VERSION "LiveWire S2 Del Mar (2024, S2DM) - Secondary CAN (DLC tap) - community reverse-engineered v0.1"

// ============================================================================
// LiveWire S2 Del Mar - Secondary CAN bus signal database
// ============================================================================
// Vehicle : 2024 LiveWire S2 Del Mar (S2DM), VIN odo ~2510 mi at capture time
// Bus     : SECONDARY CAN, tapped at the Data Link Connector [91] (JST MWT 6-way)
//           DLC pinout (from H-D EDM): pin2=W/R=CAN-H, pin5=W/BK=CAN-L,
//           pin3=BK/GN=ground, pin4=R/Y=accessory power, pins 1&6 = N/C
// Bitrate : 500000 (classical CAN, 11-bit standard IDs)
// Members : BCM (gateway/network mgr), TCU, IM, DLC   [per H-D EDM topology]
// NOTE    : PEU/RESS/EHCU/IMU/RHCM/LHCM are on PRIMARY CAN, NOT visible here.
//           Motor/inverter/BMS broadcast data is on primary; reach it via UDS
//           through the BCM gateway (0x7Ex addresses seen on this bus).
//
// Byte convention in comments: D1..D8 = SavvyCAN export columns = CAN data[0..7]
// In DBC start-bit terms below, big-endian (Motorola) signals are used where the
// capture showed BE multi-byte values.
//
// Verification method (general):
//   Isolated single-action captures, differential analysis (before/during/after),
//   cross-checked across multiple independent captures. Timestamps were logged as
//   0 (ESP32RET/A0 export bug) so sequence-order + rider action logs were used as
//   the time axis. Where a physical reference existed (odometer mi, indicated
//   speed), decoded values were checked against it.
//
// Confidence tags in comments: [CONFIRMED] cross-verified >=2 ways;
//   [STRONG] single clean capture, physically consistent; [TENTATIVE] needs more data
// ============================================================================
//
// ===== FRAME INTEGRITY (E2E) - CRACKED =======================================
// ~36 high-rate frames carry AUTOSAR-style END-TO-END protection:
//   D7 = ALIVE COUNTER, 6-bit, increments 0..63 then wraps to 0.
//   D8 = CRC-8 / SAE-J1850  (poly 0x1D, init 0xFF, xor-out 0xFF, refin/refout=NO)
//        computed over D1..D7 (the 7 preceding bytes, INCLUDING the counter).
//        This is the AUTOSAR E2E Profile-1 CRC, applied to the raw 7 payload bytes
//        WITHOUT a Data-ID prefix - a J1850-CRC E2E-like scheme, simpler than
//        textbook Profile 1 (no per-message Data ID folded into the CRC).
//   Python: crc=0xFF; for b in D1..D7: crc^=b; 8x{ crc=((crc<<1)^0x1D)&0xFF if
//           crc&0x80 else (crc<<1)&0xFF }; checksum = crc ^ 0xFF
//   PROTECTED IDs (D7=alive ctr, D8=CRC): 0x122 124 126 128 12A 131 133 134 152
//     154 15A 160 161 162 163 164 180 181 182 183 184 185 186 187 188 189 1A6
//     1A7 1C7 1C9 260 322 324 35A 3C8 562.  Verified 100% frame match. Use it to
//     VALIDATE a decode (a mis-aligned read fails CRC) and to detect dropped frames
//     (counter gaps).
//   UNPROTECTED IDs (D7 & D8 CONSTANT padding, no per-frame integrity): 0x136 138
//     261 262 326 328 332 334 338 33A 33C 33E 354 392 394 395 3C4 3C6 3CA 3CC 3CE
//     3CF. A few carry an internal counter mid-frame (0x3C4 D3, 0x3C6 D5) but no CRC.
//     NOTE: even the fast 0x326 (wheel speeds) is unprotected - protection tracks the
//     authoring module / signal criticality, not the frame rate.
//
// ===== ID-MAP PROVENANCE =====================================================
// The S2 does NOT reuse the combustion-Harley CAN map: 0x383 (radio), 0x521 (speed),
// 0x530, 0x540/0x541 (engine), 0x544 (throttle), 0x5C1 (clock) are ALL ABSENT - a
// purpose-built EV ID map, not a warmed-over platform DBC (despite shared module
// architecture). Some frames are ALLOCATED-BUT-EMPTY reserved slots: 0x394 / 0x3CA /
// 0x3CF read all-zero; 0x328 / 0x3CC are sentinel-filled (0xFF/0xFE) placeholders.
// Stack is AUTOSAR (per the E2E CRC-8/J1850); the IM is a Harley first-party module,
// software-versioned via Harley SIP (e.g. LiveWire Instrument Module 02.02.00). No
// public community CAN documentation exists for the LiveWire - this DBC is novel.
// ============================================================================
// ---- 0x122 (290) : IMU 3-AXIS ACCELEROMETER (lean/tilt) - CONFIRMED ----------
// [RESOLVED - 3-AXIS ACCELEROMETER, see BO_ below] 0x122 is not six independent bytes - it is
//   THREE 16-BIT PAIRS with an offset-binary (signed) encoding:
//     D1:D2, D3:D4, D5:D6, each with value - 32768 giving a signed number.
//   Evidence: D1, D3, D5 take only ~2 values each (~128, ~128, ~97) i.e. they are
//   HIGH BYTES sitting near the 0x8000 signed-zero point, while D2, D4, D6 sweep
//   247/241/223 distinct values as low bytes. Decoded that way the ranges are
//   sensible: D1:D2 = -56..+137, D3:D4 = -253..+37, D5:D6 = -7865..-7654.
//   WHAT THEY ARE NOT: correlated against speed, motor load, battery flow and
//   acceleration over 2469 paired samples, every r is between -0.06 and +0.08 -
//   i.e. no relationship to any vehicle dynamic we have decoded. Specifically NOT
//   battery power (that hypothesis was tested and failed).
//   These are the highest-resolution unexplained channels on the bus and the most
//   likely place for something significant still to be hiding.
//   HISTORICAL NOTE: earlier passes examined D2/D4/D6 as standalone bytes, which is
//   why they looked like noise - the pairing was the missing piece.
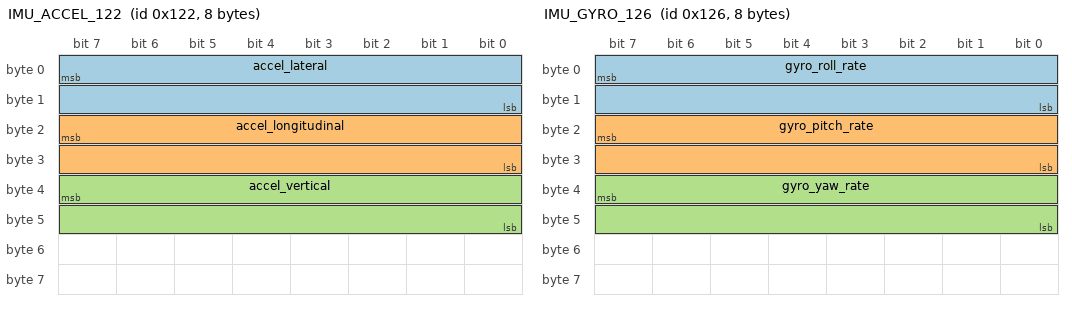
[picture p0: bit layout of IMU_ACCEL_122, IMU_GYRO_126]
BO_ 290 IMU_ACCEL_122: 8 IM
 SG_ accel_lateral      : 7|16@0+ (1,-32768) [-32768|32767] "count" Vector__XXX
 SG_ accel_longitudinal : 23|16@0+ (1,-32768) [-32768|32767] "count" Vector__XXX
 SG_ accel_vertical     : 39|16@0+ (1,-32768) [-32768|32767] "count" Vector__XXX

// [CONFIRMED] 0x122 = 3-AXIS ACCELEROMETER (IMU), gatewayed from primary CAN. Three
//   signed 16-bit channels, offset-binary (physical value = raw - 32768):
//     D1:D2 = LATERAL / roll axis    (lean LEFT = positive, lean RIGHT = negative)
//     D3:D4 = LONGITUDINAL / pitch   (level ~+175; NOSE-DOWN tilt drops it to ~-110)
//     D5:D6 = VERTICAL axis          (~ -7770 at rest = -1 g)
//   SCALE ~7770 counts per g (from the resting vertical channel).
//   PROVEN by lean_3xl_3xr (bike rocked by hand on the sidestand, 3x left then 3x
//   right):
//     - D1:D2 swung +786..+1211 on the THREE left leans and -1024..-1525 on the
//       THREE right leans - signed and symmetric by direction. Clean 3L/3R pattern.
//     - D5:D6 magnitude SHRANK toward zero on every lean (-7770 -> -7617 at hardest),
//       exactly as gravity tilts off the vertical axis.
//     - VECTOR MAGNITUDE CONSERVED: sqrt(D1D2^2 + D3D4^2 + D5D6^2) held ~7770 across
//       all orientations = a constant 1 g gravity vector rotating between axes. At
//       the biggest right lean sqrt(1525^2 + 7617^2) = 7768 ~= rest 7770. That
//       conservation is the definitive accelerometer signature.
//   Implied lean angles were gentle hand-rocks: asin(1525/7770) ~= 11 deg right,
//   asin(1211/7770) ~= 9 deg left.
//   PITCH AXIS INDEPENDENTLY VALIDATED by a natural experiment (stand geometry):
//   ordering captures by odometer, D3:D4 held ~+175 (level) through EVERY front-wheel
//   test, then STEPPED to ~-110 exactly at the forklock capture - the moment the
//   front wheel came off the stand and the bike tilted nose-down onto the rear stand
//   only. Cleanest A/B: idle_94f (front stand ON) D3:D4=+175 vs idle_forward_tilt
//   (front stand removed) D3:D4=-112 = a 287-count step = asin(287/7770) ~= 2.1 deg
//   forward tilt, while D5:D6 (vertical) and D1:D2 (lateral) barely moved - a pure
//   fore-aft rotation, exactly as a pitch axis must behave. So ALL THREE axes are now
//   independently validated (lateral=lean test, vertical=gravity magnitude, pitch=
//   stand tilt). NOTE this means the "pitch NOT found on secondary" entry in the
//   speculation doc is also overturned - it was there all along in D3:D4.
//   *** OVERTURNS the speculation-doc "tilt/lean NOT on secondary" conclusion. The
//   IMU is a primary-bus module but its accel IS gatewayed here. The reason 0x122
//   never correlated with speed/power (which killed the battery-power idea) is that
//   an accelerometer reads GRAVITY at rest, not vehicle dynamics - the tell was the
//   near-constant -7770 vertical channel all along.
//   COMPANION FRAME: 0x126 is the matching 3-AXIS GYROSCOPE (CONFIRMED) - see its
//   block immediately below. Together 0x122 (accel) + 0x126 (gyro) form a full
//   6-AXIS IMU gatewayed onto secondary CAN.
// ---- 0x126 (294) : IMU 3-AXIS GYROSCOPE (angular rate) - CONFIRMED -----------
BO_ 294 IMU_GYRO_126: 8 IM
 SG_ gyro_roll_rate  : 7|16@0+ (1,-32768) [-32768|32767] "count" Vector__XXX
 SG_ gyro_pitch_rate : 23|16@0+ (1,-32768) [-32768|32767] "count" Vector__XXX
 SG_ gyro_yaw_rate   : 39|16@0+ (1,-32768) [-32768|32767] "count" Vector__XXX

// [CONFIRMED] 0x126 = 3-AXIS GYROSCOPE (angular RATE), same structure as the 0x122
//   accelerometer: three signed 16-bit pairs, offset-binary (value = raw - 32768):
//     D1:D2 = ROLL rate    (responds to SIDE-TO-SIDE shaking)
//     D3:D4 = PITCH rate   (responds to FORWARD-BACK shaking)
//     D5:D6 = YAW rate     (third axis; responded to both hand-shakes because manual
//                           input is never a pure single axis - treat yaw as [STRONG])
//   PROVEN by shakenbabysyndrome_sidetoside_forwardback_5xeach (bike shaken on the
//   stand, 5x side-to-side then 5x fore-aft):
//     - AXIS MATCH: D1:D2 (roll) oscillated hard in the SIDE-TO-SIDE burst and went
//       quiet in the fore-aft burst; D3:D4 (pitch) did the opposite - one-to-one with
//       the 0x122 accel roll/pitch axes.
//     - RATE-NOT-ANGLE (definitive): within the side-to-side burst, D1:D2 correlates
//       r=-0.68 with the DERIVATIVE of the 0x122 roll ANGLE, and only r=-0.05 with the
//       angle itself. Angular rate = d(angle)/dt, ~90 deg out of phase with angle -
//       exactly a gyro. Peak-to-peak (7826) exceeded the accel's (4362), as expected
//       for a rate driven by fast motion.
//   SCALE: raw counts; deg/s per count NOT pinned (needs a known rotation rate, e.g. a
//   turntable - not worth chasing for a display/telemetry feed).
//   HISTORY: 0x126 was long dismissed as noise / "0xFFFE not-available". The sentinel
//   just means that gyro axis is idle/unpopulated in some states; under motion all
//   three pairs come alive. With 0x122 (accel) this completes the IMU on secondary.
// ---- 0x128 (296) : PROPULSION / ABS STATUS (E2E, sparse ~0.2 Hz) -----------
BO_ 296 PROPULSION_ABS_128: 8 Vector__XXX
 SG_ front_brake_applied_128 : 47|8@0+ (1,0) [0|255] "" Vector__XXX

// [CANDIDATE 2026-07-29 — "triangle-!" whole-suite WARNING-ICON fingerprint] Rider triggered the dash
//   warning icon on a real ride (s60) and rebooted to clear it (s61). An A/B (s60 warning vs s61
//   cleared-post-reboot + s59 normal, all controlled for riding) isolates a LATCHED ABS/traction
//   signature persisting until power-cycle, across THREE EHCU/motor frames:
//     0x128 D5 : 0x10 -> 0x70        (this frame's hard-decel/ABS-regen control block, heavily flagged)
//     0x161 D6 : 0x04/0x14 -> 0x74   (motor_status: extra 0x60 bits above the 0x10 limiter = DERATE)
//     0x3C8 D3 : 0x3F/0xDF -> 0xFF   (ABS status/validity word, all bits)
//     0x505 D1 : 0x00 -> 0x01        (latched power/boot flag)
//   All ABS/TC/limiter-class => matches the rider's "ABS/TC warning" read, and the motor-derate bit
//   implies it also LIMITS power (limp mode). RULES OUT the old 0x152 D2=0x0E lighting telltale (0x00
//   here). MODE CONFOUND REMOVED: the normal ride s59 was the SAME mode as s60 (0x44 = Eco/Range) yet
//   shows the NORMAL values, so the latch is warning-specific, NOT mode-driven. Remaining CAVEAT:
//   single occurrence, no onset, no live DTC captured. Confirm with the ONSET + a live DTC read while
//   the warning is present. See docs/livewire_s2_CAN_speculation.md.
// [CONFIRMED 2026-07-29 — 6-session review] D6 (front_brake_applied_128) = FRONT-BRAKE-APPLIED flag:
//   0x01 off / 0x02 on. Thresholded with hysteresis on the 0x324 front-brake pressure (sets ~200-270
//   raw, clears ~90-130). D6 vs 0x324 r = +0.81..0.91 across SIX sessions. DISCONFIRMED as rear/regen
//   by the s57 hard-regen event (tq=-260, rbrk=16, fbrk=0 -> D6 stayed 0x01). SUPERSEDES the frame-
//   catalog "0x128 D6 = 2-state status bit, unattributed." (EHCU/ABS = Bosch MSC; a front-pressure
//   threshold flag is native to that unit.)
//   D3/D4/D5 = [CANDIDATE] hard-decel / regen-control block - activate together ONLY during sustained
//   strong regen/hard braking (zero at standstill/cruise/accel; dissociated from the front-brake
//   flag: active with fbrk=309 in s28 AND fbrk=0 in s57, common factor tq~=-198 regen). D5 0x20 =
//   control-active bit; D3 = phase index {18,19}; D4 = 0-211 sawtooth (ABS/regen-blend modulation
//   output, NOT a clean magnitude). Single-event-per-session -> needs a graded/near-ABS braking
//   capture to settle (see the 0x128 census caveat + speculation doc). D7/D8 E2E.
// ---- 0x12A (298) : off-throttle / regen-active flag -------------------------
BO_ 298 STANDSTILL_FLAG_12A: 8 Vector__XXX
 SG_ standstill : 31|8@0+ (1,0) [0|255] "" Vector__XXX

// [UPDATE 2026-07-27 — ride1 real-timestamp capture + deep review; double-verified.
//  RETRACTS "off_throttle_regen". 0x12A D4 = 0x40 is a debounced VEHICLE-STANDSTILL
//  flag (Bosch-style), NOT a regen indicator.]
//   Sets ~0.4 s after speed reads 0; clears ~0.34-0.56 s after sustained motion;
//   THROTTLE-INDEPENDENT (held through 22.5% launch throttle at 0 km/h). Transitions
//   ride the normal 200 ms grid.
//   REGEN MODEL KILLED BOTH WAYS: 0x00 through the ENTIRE 75mph passive-regen coast
//   and every ride1 regen phase; 0x40 held while throttle applied at standstill.
//   Corpus-wide: ZERO instances of 0x40 while moving (a hard invariant -> validate.py).
//   [REVERSE CORROBORATION 2026-07-30, ultracode] D4 is a standstill/drive-engaged flag, NOT a
//     direction bit: 0x00 in BOTH reverse-drive AND forward-drive, 0x40 only at idle/standstill
//     (reverse2x: 0x00 in 34 reverse-drive + 43 forward-drive rows, 0x40 in 124 idle rows). It
//     is the sole status byte that moves between regimes, and it tracks engagement not direction.
//   The old "0x40 during coast/regen" reading was standstill coincidentally co-occurring
//   with the end of those low-speed bench tests.
//   QUALIFIED: standstill is NECESSARY but not SUFFICIENT - a gating condition also
//   applies (candidates: dynamics-suite-valid, or 0x162 D4 state; ~5 s power-on
//   latency; 0x40 absent in gyro-0xFFFE rows). D4=0x80 is a THIRD state seen only in
//   mode-sweep captures, coincident with 0x134 entering/leaving 0x55/0x88/0x99 at
//   standstill (mode-hold). Both unresolved - see the speculation doc.
//   *** [RETRACTED 2026-07-29 — was "[NEW 2026-07-28] 0x12A D1 = a 2-LEVEL SPEED-BAND FLAG (0x40
//   rest/low, 0x80 above a speed threshold)"]: the speed-band read FAILS on full speed overlap -
//   s54 has 945-raw speed at 0x40 vs 237-raw at 0x80, so the two levels' speed distributions fully
//   OVERLAP. What actually happens: 0x12A D1 = a MOTION-GATED PARITY/ALTERNATION bit - it flips
//   0x40<->0x80 on essentially every consecutive MOVING frame (alternation 0.92/1.00/1.00/1.00 over
//   s28/s31/s44/s57) and is pinned to 0x40 at standstill. 0x80 is simply SUPPRESSED at standstill,
//   which is why its mean speed looked higher earlier (a gating artifact, not a speed band). Toggle
//   PASS (deterministic, 4 sessions); NOT a signal to wire. (Old speed-band means kept above for the
//   record: they were the standstill-suppression artifact, not a threshold.) ***
// ---- 0x133 (307) : see IGNITION_REAR_BRAKE_133 below (merged) ---------------
// ---- 0x134 (308) : RIDER SETTINGS status (mode + TC + related) ---------------
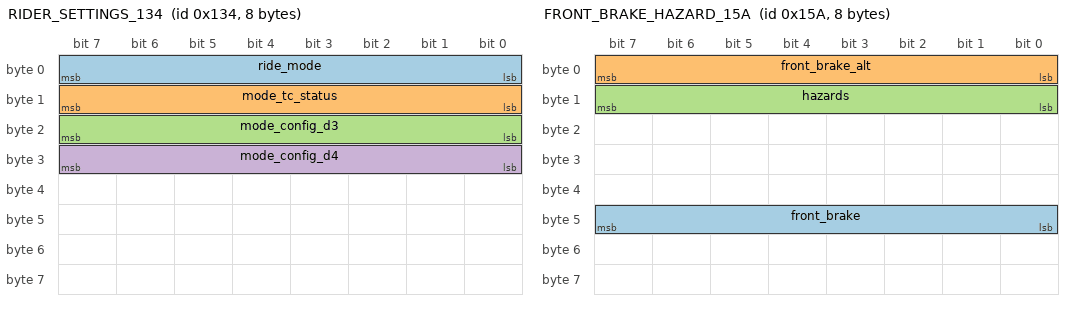
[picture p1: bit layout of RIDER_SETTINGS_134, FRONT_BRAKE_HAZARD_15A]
BO_ 308 RIDER_SETTINGS_134: 8 BCM
 SG_ ride_mode      : 7|8@0+ (1,0) [0|255] "" Vector__XXX
 SG_ mode_tc_status : 15|8@0+ (1,0) [0|255] "" Vector__XXX
 SG_ mode_config_d3 : 23|8@0+ (1,0) [0|255] "" Vector__XXX
 SG_ mode_config_d4 : 31|8@0+ (1,0) [0|255] "" Vector__XXX

// [CONFIRMED] 0x134 D1 = ride-mode enum (high nibble = mode id):
//   0x22 Sport, 0x11 Street, 0x44 Eco, 0x33 Rain, 0x88 custom-A, 0x99 custom-B,
//   [NAMING 2026-07-29] "Street"/"Eco" were the rider's labels; per the OEM manual the factory modes
//   are Sport/Road/Range/Rain/Flat Track -> 0x11 Street = ROAD, 0x44 Eco = RANGE (Custom A/B are the
//   two app-programmable slots). All seven codes now confirmed via 3 mode-cycle captures.
//   0x55 = SEVENTH MODE (see below). Verified by cycling Sport->A->B->Rain->Eco->
//   Street->Sport and observing 0x134 D1 step 22->88->99->33->44->11->22 (clean
//   closure). 0x260 D1 mirrors.
// [CONFIRMED] 0x55 = FLAT TRACK MODE (the "hard lean" rider icon). Rider confirms
//   the leaning-rider mode IS Flat Track. It is reached by "activating" (hold Mode
//   in) SPORT: activating Sport does NOT keep id 0x22 with an overlay bit - it SWITCHES
//   the mode id to 0x55 (seen twice in modes_alltryactivated: 22 -> 55 -> 22 -> 55). So
//   Flat Track is Sport's activated variant, promoted to its own dedicated mode id.
//   It runs the Sport-tier power index (D3 low-nibble = 3, D4=0x30) with rear ABS off
//   (0x3C8 D4 bit7 set), its own default TC nibble (D2 = 0x54; low-nibble 4, distinct
//   from Sport's 3), and TC is still rider-toggleable to off (D2 = 0x59, low-nibble 9 -
//   confirmed by the modes_alltryactivated finale where the rider hand-disabled TC in
//   Flat Track: D2 went 0x54 -> 0x59). NOTE: this is NOT the "triangle-!" fault state
//   the rider once hit - Flat Track cuts REAR ABS ONLY and keeps TC available; the
//   fault dropped the WHOLE aid suite (TC + front & rear ABS). See 0x3C8 / fault notes.
// [CONFIRMED] THE "ACTIVATED" MODE VARIANT (hold the Mode button). Marked on the bus by
//   0x134 D3 HIGH NIBBLE 1 -> 4 (power-index low nibble UNCHANGED) and 0x134 D6 bit2
//   (0x04). Full sweep of activating all 7 modes (modes_alltryactivated) shows only
//   THREE modes have a functional activated variant, and each SWITCHES/overlays thus:
//     Sport (22) -> FLAT TRACK, id 0x55, D3=43, D6=04   (own mode id)
//     CustA (88) -> "Purple A",       D3=48, D6=04   (id stays 88, purple display)
//     CustB (99) -> "Purple B",       D3=49, D6=04   (id stays 99, bold/purple display)
//   Street/Rain/Eco: activating them produces NO change on secondary CAN at all (D3
//   high-nibble stays 1, D6 stays 0, rear ABS stays on) - matches rider's "only Sport
//   ->Flattrack and A/B->Purple were noticeable".
//   *** ACTIVATED vs REAR ABS OFF = SEPARATE axes, correlated only by CURRENT CONFIG. ***
//   Custom A/B are USER-PROGRAMMABLE from the LiveWire app, so what a mode's "activated"
//   variant DOES (rear ABS, TC, power) is itself configurable. The 100% co-occurrence we
//   see (every activated variant here also cuts rear ABS) therefore reflects how THIS
//   bike's A/B (and the factory Flat Track) are currently programmed - NOT an intrinsic
//   bus-level equivalence. Read the two signals as independent:
//     - 0x134 D6 bit2 / D3-hi=4  = "activated variant engaged" (generic state flag)
//     - 0x3C8 D4 bit7            = "rear ABS disabled" (a CONSEQUENCE that the mode's
//                                   programmed settings may or may not include)
//   The firmware keeps them as separate signals precisely because they are independently
//   configurable. DEFINITIVE DECOUPLE (now controllable, no fault needed): in the app,
//   program custom A's activated variant to KEEP rear ABS on, then capture - D6 bit2 will
//   set while 0x3C8 D4 bit7 stays 0. That single capture converts this from "correlated
//   under current config" to a clean independent proof. Until then: do NOT infer rear ABS
//   state from the activated flag or vice-versa; match each bit to its own frame.
// [CONFIRMED] 0x134 D2 = mode(high nibble) + status(low nibble). Low nibble
//   carries Traction Control state: within Sport, TC-on=0x23, TC-off=0x29
//   (i.e. low nibble 3=on, 9=off). Verified via idle TC-on->TC-off capture
//   (single toggle 0x23->0x29 at the switch press) AND independently the whole
//   75mph TC-off run read 0x134 D2 = 0x29 throughout.
//   CAUTION: D2 is a mode+status bitfield, not a pure TC bit. Match the low
//   nibble for TC, use D1 for mode. Other modes may set other low-nibble values
//   (Rain/Eco seen with different low nibbles) - treat unseen values as unknown.
// [CONFIRMED per-mode] 0x134 D3 and D4 are PER-MODE CONFIG bytes - each takes a
//   DETERMINISTIC value for every one of the 6 modes (cyclemodes capture):
//     mode    D1  D3  D4    0x260 D2
//     Sport   22  13  30    20
//     Street  11  11  10    10
//     Eco     44  1D  D0    40
//     Rain    33  2C  C0    30
//     CustA   88  18  80    80
//     CustB   99  19  90    90
//   ACTIVATED VARIANTS (hold Mode; D3 high-nibble=4, D6 bit2=1, rear ABS off):
//     FlatTrk 55  43  30    50   <- activated SPORT = Flat Track (own mode id 0x55)
//     PurpleA 88  48  80    80   <- activated CustA (id stays 88)
//     PurpleB 99  49  90    90   <- activated CustB (id stays 99)
//   (Street/Rain/Eco have NO functional activated variant on the bus.)
//   STRUCTURE: 0x134 D3 low-nibble == D4 high-nibble == a per-mode index
//   (3/1/D/C/8/9 for Sport/Street/Eco/Rain/CustA/CustB), and 0x260 D2 high-nibble
//   mirrors the mode id. So these carry the mode's SETTINGS bundle (regen level,
//   power map, throttle map). SEMANTIC split of the sub-fields is UNRESOLVED - would
//   need ground truth on each mode's actual regen/power settings to attribute which
//   nibble is which. For now: deterministic per-mode, usable to read the active mode
//   three independent ways (D1, D3/D4 index, 0x260 D2).
// ---- 0x15A (346) : FRONT brake lever + hazards ------------------------------
BO_ 346 FRONT_BRAKE_HAZARD_15A: 8 BCM
 SG_ front_brake : 47|8@0+ (1,0) [0|255] "" Vector__XXX
 SG_ front_brake_alt : 7|8@0+ (1,0) [0|255] "" Vector__XXX
 SG_ hazards     : 15|8@0+ (1,0) [0|255] "" Vector__XXX

// [CONFIRMED] 0x15A D6 = FRONT brake lever: 0x00 released -> 0x40 pressed.
// [CONFIRMED] 0x15A D1 = SECOND front-brake indicator: 0x10 released -> 0x01
//   pressed. Perfectly correlated with D6 (224 frames at 0x01 while pressed,
//   6736 at 0x10 while released, zero disagreement) in the fast-spin + 3x front
//   brake capture. Either byte works; D1 is a cleaner 2-state read.
//   Isolated in brakelight_front_rear_passiveregen capture: active ONLY during
//   the front-brake segment, not rear, not regen. (0x15A D1 also moves front:
//   0x10->0x01.) 0x15A D2 remains hazards (0x00<->0x10) - same frame, diff byte.
// ---- 0x133 (307) : ignition + REAR brake ------------------------------------
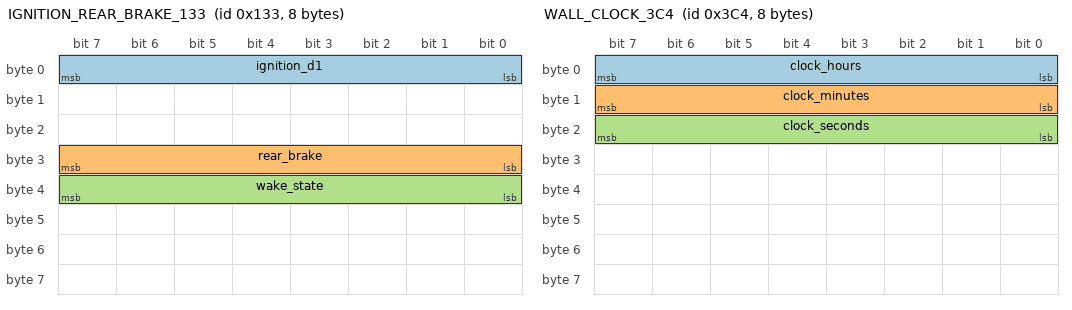
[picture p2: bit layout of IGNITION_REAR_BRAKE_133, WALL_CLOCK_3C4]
BO_ 307 IGNITION_REAR_BRAKE_133: 8 BCM
 SG_ ignition_d1 : 7|8@0+ (1,0) [0|255] "" Vector__XXX
 SG_ rear_brake  : 31|8@0+ (1,0) [0|255] "" Vector__XXX
 SG_ wake_state  : 39|8@0+ (1,0) [0|255] "" Vector__XXX

// [CONFIRMED 2026-07-28] 0x133 D5 = WAKE / ignition sub-status. 0x10 = awake/on in
//   EVERY powered state (idle E0, ride E0, charge 50), 0x20 = deep-off (only appears
//   in the ignition/boot transient alongside D1=0x20 OFF). Zero counterexamples across
//   the corpus; E2E CRC-clean. Distinct from D1 (system-state enum) - a coarser on/off.
// [CONFIRMED] 0x133 D4 = REAR brake lever: 0x00 released -> 0x10 pressed.
//   Isolated: active ONLY during the rear-brake segment (first time rear was
//   pressed in any capture). Front and rear are SEPARATE IDs - that's why the
//   earlier single-byte 0x136 guess failed.
//   ROBUSTNESS: rear LAMP was physically UNPLUGGED during this capture, yet
//   0x133 D4 still toggled cleanly => it is the LEVER SWITCH state, independent
//   of the bulb. No rear-bulb-out fault flag appeared on secondary in this
//   capture (a bulb-out fault, if any, may be on primary CAN or via UDS only).
// [CONFIRMED] 0x133 D1 = SYSTEM STATE enum (not just ignition on/off):
//     0x20 = OFF
//     0x60 = ignition ON, motor NOT enabled (accessory / stand-by)
//     0x80 = ENABLING (brief transitional state during START press)
//     0xE0 = MOTOR ENABLED / ready-to-drive
//     0x50 = CHARGING (AC charging in progress). CONFIRMED: appears in 2025 frames
//            of charge_1-1kw.csv and in NONE of the other 46 captures. The capture
//            also contains 0x60, i.e. it moves between charging and ignition-on.
//   Mapped with the full ign->enable->roll->brake->disable->off sequence capture.
//   (An earlier ignition-only capture never enabled the motor, so it only ever
//   showed 0x20/0x60 - hence the earlier incomplete "on/off" decode.)
// ---- 0x152 (338) : lighting + ignition bitfields ----------------------------
BO_ 338 LIGHTING_152: 8 BCM
 SG_ highbeam   : 23|8@0+ (1,0) [0|255] "" Vector__XXX
 SG_ ign_152_d2 : 15|8@0+ (1,0) [0|255] "" Vector__XXX

// [STRONG] 0x152 D3 = high beam: 0x00<->0x04. Verified highbeam_on_2x capture.
//   D2 (byte 1) is a shared lighting/ignition bitfield (0x00/0x10/0xE0 at ignition) AND
//   carries a LATCHED WARNING TELLTALE at value 0x0E: 0x00 normal -> 0x0E warning, held ON
//   even at a standstill from ride session s15 onward (motion-INDEPENDENT, so NOT a headlight
//   beam), with NO stored DTC (rider ran diagnostics -> "no faults"). Rider attributes it to
//   an ABS/TC-related warning. [RIDE-CONFIRMED 2026-07-28; corrects the earlier "D2 = beam
//   bitfield" reading for the 0x0E value — that specific value is a warning telltale.]
// ---- 0x131 (305) : turn signal LAMP STATUS (live bulb on/off + side) --------
BO_ 305 TURN_LAMP_131: 8 BCM
 SG_ lamp_left  : 23|8@0+ (1,0) [0|255] "" Vector__XXX
 SG_ lamp_right : 31|8@0+ (1,0) [0|255] "" Vector__XXX

// [CONFIRMED] 0x131 D3/D4 = LAMP STATUS (blinks at flash cadence = live bulb):
//   resting (off) = (D3=0x15, D4=0x50).
//   Left lamp lit : D3 0x15 -> 0x19   (blinks ~16 frames off / 17 on)
//   Right lamp lit: D4 0x50 -> 0x90   (blinks)
//   Hazards       : BOTH D3 and D4 blink (0x19 / 0x90)
//   This is the LAMP layer: D3/D4 oscillate ON<->OFF at the flash rate, so a
//   snapshot tells you whether that bulb is CURRENTLY lit. Use for a live blink
//   effect. Decode side: left uses D3, right uses D4.
//   Verified: left_signal_2x (only D3 blinks), right_signal_2x (only D4 blinks),
//   hazards_2x (both blink), idle (neither) captures.
// [REFINED 2026-07-29 — was "0x154 D4/D5 ... repeater artifact, do not use for turn state"]
//   0x154 D4/D5 is a STRUCTURED L/R TURN-SIGNAL REPEATER lane (promoted to BO_ 340 below), NOT
//   noise: every D4=0x10 aligns to 0x131 D3=0x19 (LEFT lit), every D4=0x01 aligns to 0x131 D4=0x90
//   (RIGHT lit), and D5=0x10 fires on the off-phase edges between D4 pulses. ~25 clean events across
//   s54+s57 with ZERO disagreement. 0x131 D3/D4 REMAINS the lamp source; 0x154 is a downstream echo
//   (usable as an L/R repeater, not as the primary turn state).
// ---- 0x154 (340) : TURN-SIGNAL REPEATER LANE (E2E) -------------------------
BO_ 340 TURN_REPEATER_154: 8 BCM
 SG_ turn_repeater_lr       : 31|8@0+ (1,0) [0|255] "" Vector__XXX
 SG_ turn_repeater_offphase : 39|8@0+ (1,0) [0|255] "" Vector__XXX

// [STRONG 2026-07-29] Downstream repeater of the 0x131 turn lamps: D4 (turn_repeater_lr) 0x10 =
//   LEFT (aligns 0x131 D3=0x19), 0x01 = RIGHT (aligns 0x131 D4=0x90); D5 (turn_repeater_offphase)
//   0x10 fires on the off-phase edges between D4 pulses. ~25 clean events s54+s57, zero disagreement.
//   0x131 remains the lamp SOURCE - this is an echo lane. D1/D2 = [CANDIDATE] extra Slow-mode
//   indicator lanes (0x01/0x10, single session s57, not turn-driven; see speculation doc). D7/D8 E2E.
// ---- 0x3C4 (964) : UNKNOWN (contains rolling counters) ----------------------
BO_ 964 WALL_CLOCK_3C4: 8 BCM
 SG_ clock_hours   : 7|8@0+ (1,0) [0|23] "h" Vector__XXX
 SG_ clock_minutes : 15|8@0+ (1,0) [0|59] "min" Vector__XXX
 SG_ clock_seconds : 23|8@0+ (1,0) [0|59] "s" Vector__XXX

// [CONFIRMED 2026-07-28, frame-catalog + empirical verify] 0x3C4 D1:D2:D3 = REAL-TIME
//   CLOCK, hours:minutes:seconds. In newcap_4 (real timestamps) D3 (seconds) ticks +1/s
//   and wraps at 0x3B=59 exactly as D2 (minutes) increments; D1 = hours-of-day (max 0x17=23).
//   Clock advanced 116 s over 116 s of real time (ratio 1.003); 0 range violations. Free-
//   running through the ~8-min IM brownout (D2 38->46 across the gap) -> a wall clock, NOT
//   an uptime counter.
//   [REFINED 2026-07-30, ultracode round - cross-capture] 1:1 advance RE-CONFIRMED (s57
//   1502 clock-s over 1501.5 real-s, ratio 1.0003, monotonic). NOT civil-UTC-synced: the
//   clock-to-filename offset is a CONSTANT +6h38m across s57/s61/s60/s59/s28 (~10 s spread),
//   not the +7h that July PDT (UTC-7) would require -> a FREE-RUNNING clock with a fixed
//   offset (~22 min short of UTC), NOT GPS/civil-time-locked. Retracts the "GPS-synced" guess.
//   *** RESOLVES the old "0x3C4 D2 multi-purpose status byte" TODO: the "turn-intent"
//   0x0E/0x10/0x14 and the ABS-test 0x15/16/17 values were simply the MINUTES-of-recording
//   of those captures. RETRACTS notes.md's "No wall clock" claim. ***
//   D4=0x00, D5=0x30, D6=0x03 constant. Use 0x131 D3/D4 for turn state, not this.
// ============================================================================
// ROUND-6 FRAME CATALOG (2026-07-28) - the frames previously dismissed as
//   "reserved / heartbeat / echo", each now characterized. 9/18 carry real state,
//   7 confirmed inert. FULL per-ID detail + evidence: docs/livewire_s2_CAN_frame_catalog.md
// ============================================================================
// ---- 0x136 (310) : BCM DRIVE-READY STATE MACHINE (non-E2E, ~1 Hz) ----------
BO_ 310 DRIVE_READY_136: 8 BCM
 SG_ drive_ready_state : 7|8@0+ (1,0) [0|255] "" Vector__XXX

// [STRONG] D1 enum: 0x44 = drive-ENABLED/RUN, 0x33 = powered READY-but-not-enabled (D2/D3/D6
//   coded redundantly: 41/10/FD run vs 32/20/FC ready). Deterministic power-up sweep then
//   settles; flips to ENABLED only after the roll-enable step. = propulsion enabled vs standby.
// ---- 0x138 (312) : BCM LIVENESS HEARTBEAT (non-E2E) ------------------------
BO_ 312 HEARTBEAT_138: 8 BCM

// [CONFIRMED inert] Fixed payload D2=0x40 (else 0x00) in all 61 captures incl. the brownout
//   fault. No counter/CRC. Value is presence-only (module liveness).
// ---- 0x184 (388) : VSC PROPULSION STATUS (E2E, ~2.5 Hz) --------------------
BO_ 388 PROPULSION_STATUS_184: 8 Vector__XXX
 SG_ drive_state_184     : 39|8@0+ (1,0) [0|255] "" Vector__XXX
 SG_ tc_intervention_184 : 47|8@0+ (1,0) [0|255] "" Vector__XXX

// [STRONG] D5 (drive_state_184) speed-INVERSE (r=-0.80 vs rpm): 30 coast->20 moving->10 hard.
//   D6 (tc_intervention_184) flat 0xF0, steps F0->F1->F2 only in ride1 TC/slip = intervention
//   event indicator. D3/D4 = readiness bits (7D/90, 19/00). D7/D8 E2E. (Refines the old
//   "mostly-static; USB red-herring" note - the USB retraction stands, D5 is speed-linked.)
// [CORROBORATED 2026-07-28, s44 real timestamps] D6 fired 4 genuine TC micro-interventions
//   (F0->F1) on the hard launches: t=207.2 (thr 52%, td 542), t=333.8 (thr 80%, td 878,
//   rear-lead 44), t=335.7 (thr 34%, td 304), t=338.9 (thr 51%, td 516) - each lines up with a
//   >6% rear-wheel-lead episode (0x326) => real driven-wheel slip cut by an ACTIVE TC (TC ON,
//   rear ABS ON, no burnout, rear-lead max 8.5%). First TC micro-cuts captured on the streamed
//   corpus, confirming the D6 = TC-intervention read on true timing.
// [REFINED 2026-07-29 r1 — GRADED, not flat-0xF0] The identity (D6 = TC/slip intervention)
//   holds, but the "flat 0xF0 except discrete slip events" prose is WRONG. Under sustained fast
//   riding D6 is CONTINUOUSLY active across a graded band F0-FC with a DECAYING distribution
//   (s57: F0 27%, F1 43%, tapering off to FC) - it is a slip-intervention INTENSITY, not a
//   binary flag and not a uniform counter. The s44 discrete F0->F1 micro-cuts (each aligned to a
//   >6% rear-wheel-lead) remain valid as the low end of that same continuum.
// [CANDIDATE 2026-07-29 — pack-thermal / power-derate cluster] (comments only, not wired):
//   D1 = coarse pack-THERMAL / derate LEVEL index (range 25-30, ~6 levels; pinned 28 in
//   gentle/parked captures). In the hard s55 run (pack raw 81->101 = 41->61 degC) D1 correlates
//   r=+0.92/+0.93/+0.93 with the three 0x183 pack temps and -0.93 vs ambient.
//   *** DOWNGRADED to SPECULATIVE / UNRESOLVED 2026-07-29 r1 (adversarial QA - fails cross-session). ***
//   The single-ride s55 r=0.92 is a temp/SoC/time-COLLINEAR co-trend, and the cross-session
//   absolute levels are NON-MONOTONIC: D1 is pinned at EXACTLY 28 in 11/13 sessions spanning pack
//   temp 78-83 raw, yet s54 (pack 80-81 raw) reads 25-26 - BELOW the COOLER park sessions
//   (78-79 raw -> 28). If D1 rose with pack temp, the warmer s54 should read >= park's 28, not
//   less. This STRIKES the earlier "SURVIVES the disconfirmer: s54 stayed cool -> D1 low"
//   rationalization - s54 was NOT cool for the pack (80-81 raw) and still read low, which
//   refutes rather than confirms a temp/derate index. Purpose unresolved; do NOT wire.
//   D4 bit0 = readiness / power-NOT-limited flag: 0x19 (bit0=1) at light load -> 0x18 (bit0=0) under
//   heavy propulsion demand; clean split by drive_state_184 (D5) hi-nibble (0/1/2 light -> 9-15 hard).
//   D2/D3 = [SPECULATIVE] propulsion derate substate: D3 base 0x7D becomes a +1/frame rolling counter
//   in low-SoC/derate windows (refines the old "D3 = readiness bits 7D/90" - 0x90 was one counter
//   value); D2 hi-nibble = idle 0x50. Trigger unpinned - see speculation doc.
// ---- 0x186 (390) : HV ENERGY METER (E2E, ~1.8 Hz) -------------------------
BO_ 390 HV_ENERGY_186: 8 Vector__XXX
 SG_ trip_energy_consumed_wh  : 7|16@0+ (1,0) [0|65535] "Wh" Vector__XXX
 SG_ pack_energy_remaining_wh : 23|16@0+ (1,0) [0|65535] "Wh" Vector__XXX

// [CONFIRMED] D1:D2 (16-bit BE) = TRIP ENERGY CONSUMED since key-on, ~1 Wh/count. Up-counts on
//   discharge, DOWN-steps in regen, resets ~0 at key-on, clamps 0 while charging. Magnitude
//   scales with ride energy (s31 gentle ~40 Wh -> s55 hard ~2600 Wh -> s57 long ~3768 Wh) and
//   matches integral(0x181 V*I) to order (s55 ~2.9 kWh est vs 2600 Wh). WIDENS the old D2-only
//   8-bit meter (was hv_energy_wh) to the full 16-bit D1:D2 word - same physical meter.
// [UPDATE 2026-07-29 — 8-session review] D3:D4 (16-bit BE) = PACK ENERGY REMAINING, ~1 Wh/count.
//   Ratio 102.8-104.1 Wh per displayed-SoC% across all 8 non-trivial captures (22-100% span);
//   full = 10158-10300 Wh = the S2's ~10.3 kWh usable pack (independent spec anchor); 2277 Wh at
//   22% SoC (0.22*10300~=2266, matches). Steps DOWN on discharge, UP on charge (bidirectional).
//   *** RETRACTS the old "D3 = slow status band 0x25-0x28 [OPEN]" and "D4 = companion byte [OPEN]"
//   notes: the 0x25-0x28 band was simply the high byte at high SoC (0x25-0x28 = 9.5-10.3 kWh). ***
//   D5 [CANDIDATE, unwired] latches ~74 during CC charge (single charge session s32) - SPECULATIVE.
//   D7/D8 E2E.
// ---- 0x187 (391) : IM CLUSTER HEALTH (E2E, ~1.6 Hz) -----------------------
BO_ 391 IM_HEALTH_187: 8 Vector__XXX
 SG_ im_health : 23|8@0+ (1,0) [0|255] "" Vector__XXX

// [STRONG] D3 = IM cluster health: 0xA2 operational / 0x90 initializing-or-just-reset. Goes
//   0x90 exactly as the E2E alive-counter restarts at 0x01 (boot + at the fault restart in
//   faulted_IMoff_restarted) = catches the cluster browning out. D2=0x01 sub-type tag.
// ---- 0x189 (393) : IM TELLTALE + DRIVE DEMAND (E2E, ~17 Hz) ----------------
BO_ 393 IM_TELLTALE_189: 8 Vector__XXX
 SG_ throttle_demand : 31|8@0+ (1,0) [0|255] "" Vector__XXX
 SG_ wheelspin_event : 15|8@0+ (1,0) [0|255] "" Vector__XXX

// [CONFIRMED 2026-07-28 empirical verify] D4 (throttle_demand) = throttle/drive-demand,
//   corr +0.958 (newcap_8) / +0.869 (ride1) vs 0x161 throttle. *** CORRECTS the old "rolling
//   counter" label for this byte. *** D2 (wheelspin_event) = 0x01 ONLY in ride1 slip + ride3
//   burnout (traction-event flag). D1/D3 = broad telltale levels, D5 = blink/dim PWM phase.
// ---- 0x261 (609) / 0x262 (610) : BCM POWER-AVAILABILITY STATUS (non-E2E) ---
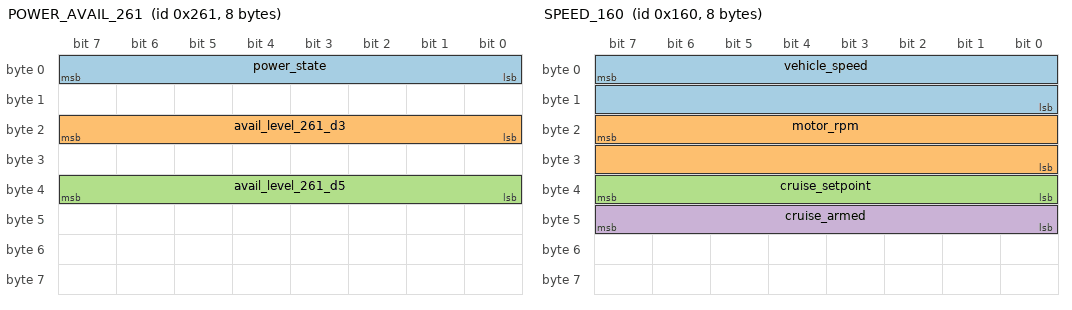
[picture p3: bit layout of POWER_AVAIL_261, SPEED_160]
BO_ 609 POWER_AVAIL_261: 8 BCM
 SG_ power_state        : 7|8@0+ (1,0) [0|255] "" Vector__XXX
 SG_ avail_level_261_d3 : 23|8@0+ (1,0) [0|255] "" Vector__XXX
 SG_ avail_level_261_d5 : 39|8@0+ (1,0) [0|255] "" Vector__XXX

BO_ 610 POWER_AVAIL_262: 8 BCM
 SG_ power_state_mirror : 39|8@0+ (1,0) [0|255] "" Vector__XXX

// [STRONG] D1 (power_state) packed: hi-nibble A=fault/init D=drive-ready E=charge/accessory;
//   lo-nibble availability. Live within-capture transitions (faulted E0->D0->AF; ks_up EC->DC).
//   0x261 D1 == 0x262 D5 exactly (internal mirror). D3/D5 = availability levels (full vs
//   reduced). *** REFUTES the old "0x261/262 BOOT-CONFIG constant" speculation: live power-
//   domain / availability STATUS, mode-independent. ***
// ---- 0x328 (808) : RESERVED SENTINEL (non-E2E) ----------------------------
BO_ 808 RESERVED_328: 8 Vector__XXX

// [CONFIRMED inert] Single payload [00 FF F0 00 00 00 00 00] across all 2019 frames / 64
//   captures. Allocated-but-empty. (Sentinel bytes are FF/F0, not FF/FE.)
// ---- 0x33C (828) / 0x3CE (974) : TWO-PHASE HEARTBEAT PAIR (non-E2E) --------
BO_ 828 HEARTBEAT_33C: 8 Vector__XXX

BO_ 974 HEARTBEAT_3CE: 8 Vector__XXX

// [CONFIRMED inert] 0x33C strictly alternates two fixed payloads A/B every-other-frame
//   (~50% duty - NOT the old "~5% cadence"): A=[40 00 00 01 09 40 80 00], B=[50 00 01 00 00
//   00 80 00]. 0x3CE is its pair (D1 toggles 0x40/0x50, [01 09 40] motif fixed). Liveness only.
// ---- 0x33E (830) : KEEPALIVE HEARTBEAT (non-E2E) --------------------------
BO_ 830 HEARTBEAT_33E: 8 Vector__XXX

// [CONFIRMED inert] Fixed payload [00 00 00 00 00 00 60 00]; only D7=0x60 marker, never
//   increments. Keepalive/liveness only.
// ---- 0x3C6 (966) : ODOMETER ECHO (non-E2E, ~3 Hz) -------------------------
BO_ 966 ODOMETER_ECHO_3C6: 8 Vector__XXX
 SG_ odometer_echo_m : 15|24@0+ (1,0) [0|16777215] "m" Vector__XXX
 SG_ odo_valid       : 47|8@0+ (1,0) [0|255] "" Vector__XXX

// [CONFIRMED] D2:D3:D4 = unprotected ECHO of the 0x562 odometer (median lag 214 ms, never
//   leads). D6 (odo_valid) = 0x30 once the odometer is valid, 0x00 during boot. Consumed by
//   the TCU. No independent content - do not read as a separate distance.
// ---- 0x3CA (970) / 0x3CF (975) : RESERVED (all-zero, non-E2E) --------------
BO_ 970 RESERVED_3CA: 8 Vector__XXX

BO_ 975 RESERVED_3CF: 8 Vector__XXX

// [CONFIRMED inert] Both all-8-bytes-0x00 in every capture. Allocated-but-empty slots in the
//   0x3Cx chassis cluster.
// ---- 0x3CC (972) : CHASSIS FAULT LATCH (non-E2E, ~0.6 Hz) ------------------
BO_ 972 FAULT_LATCH_3CC: 8 Vector__XXX
 SG_ fault_latch    : 7|8@0+ (1,0) [0|255] "" Vector__XXX
 SG_ config_gen_3cc : 23|8@0+ (1,0) [0|255] "" Vector__XXX

// [STRONG] D1 (fault_latch) = 0x7D in ALL normal states (incl. a TPMS fault), = 0x7E ONLY in
//   the IM brownout fault + ride1 TC-slip (D2 tracks: 09 normal / 39 fault). A stored fault /
//   abnormal-dynamics latch. D3 (config_gen_3cc) = slow per-session config-gen counter
//   (19->1A->1B). D4=FF,D5=FE,D6=FE sentinel tail. *** REFINES notes' "config/version head,
//   rarely updated" - the head is a STATE-LINKED fault latch. ***
// [OBSERVATION TO RECONCILE 2026-07-29 r1 — do NOT flip the decode] Across the ENTIRE streamed
//   corpus (s6..s58, all 10 sessions: park / city / freeway / charge) D1 reads 0x7E and D2 reads
//   0x39 CONTINUOUSLY - i.e. the very values this decode calls the "fault" state, in every regime
//   including calm parked baselines. D3 = the config-gen counter (0x1B->0x1C here); the D4/D5/D6
//   tail is unchanged. TWO possibilities, unresolved: (a) this specific bike carries a STANDING
//   stored-fault / abnormal-dynamics latch that never clears, OR (b) the "0x7E only-in-fault /
//   0x7D normal, 0x39 fault / 0x09 normal" assignment (derived from the legacy laptop captures) is
//   simply WRONG for this firmware/config and 0x7E/0x39 is the NORMAL idle state here. Not enough
//   evidence to choose - leaving the decode as-is and flagging the discrepancy for a future
//   known-good-state read.
// ---- 0x15A (346) : see FRONT_BRAKE_HAZARD_15A above (hazards merged there) ---
// ---- 0x160 (352) : SPEED (primary vehicle speed) + second speed/RPM ---------
BO_ 352 SPEED_160: 8 IM
 SG_ vehicle_speed : 7|16@0+ (0.1,0) [0|6553.5] "km/h" Vector__XXX
 SG_ motor_rpm     : 23|16@0+ (1,-1000) [-1000|64535] "rpm" Vector__XXX
 SG_ cruise_setpoint : 39|8@0+ (1,0) [0|255] "km/h" Vector__XXX
 SG_ cruise_armed : 47|8@0+ (1,0) [0|255] "" Vector__XXX

// [CONFIRMED] 0x160 D1:D2 (big-endian) = vehicle speed, unit km/h x10.
//   UNSIGNED: reads POSITIVE for both forward AND reverse motion (confirmed by
//   manual forward+backward spin - backward still showed positive D1:D2). For
//   direction, use D3:D4 (signed, offset 1000) instead.
//   value/10 = km/h ; (value/10)/1.60934 = mph.
//   Cross-checks: 10mph run -> 161 (=16.1km/h=10.0mph);
//                 5mph manual spin -> ~80; 75mph run peak D1:D2=1248 (=77.6mph).
//   Confirmed on the UNPOWERED manual-spin capture too => it is genuine wheel/
//   vehicle speed, independent of motor power.
// [CONFIRMED] 0x160 D3:D4 (big-endian) = MOTOR RPM + 1000 offset.
//   motor_rpm = (D3:D4) - 1000.  Positive = forward rotation, negative = reverse
//   (backward hand-spin drove D3:D4 below 1000). Signed via the offset.
//   DERIVATION (closes exactly): D3:D4 scales at 28.94 counts per km/h (regression
//   vs calibrated D1:D2 speed, r=0.998). Drivetrain from spec: motor -1:1 primary->
//   84:22 (3.818) belt -> wheel; 150/70-19 DT1 tire OD ~0.70m (circ 2.199m).
//   That gives 28.94 motor-RPM per km/h => 1.000 count per motor RPM. Exact.
//   At 103mph top speed: ~4800 motor RPM => D3:D4 ~5800. This is a true TACH.
//   Also cross-validates tire circumference ~0.70m (consistent with odometer).
//   Verified reverse via manual_spin_forward_back: forward drove D3:D4 above 1000,
//   backward below 1000, symmetric.
//   [UDS CROSS-WITNESS 2026-07-30, ultracode] VSC UDS DID 020C word0 (offset-binary 0x8000,
//     1 rpm/ct) is the point-to-point twin of this D3:D4 tach and tracks it 1:1 in reverse
//     (s8: 020C -32/-50/-90 vs 0x160 -32/-48/-88). Direction on the whole bike is recoverable
//     ONLY from this signed motor-rpm (broadcast 0x160 D3:D4 or UDS 020C) - NO drive-state
//     enum, reverse bit, or reverse-throttle level exists on secondary (see 0x161 block + a
//     66-file corpus scan). Reverse is a SUB-STATE of enabled DRIVE, sign-differentiated only.
// [CONFIRMED] 0x160 D5 = CRUISE SET-POINT SPEED, in km/h (integer), 0 when not
//   engaged. This is the ENGAGED/SET state, distinct from merely armed.
//   PROOF OF ISOLATION: D5 = 0x00 in ALL 34 other captures - including the
//   cruise-ARMED-but-never-SET capture (cruisecontrol_3x_onoff). It only becomes
//   non-zero once cruise is actually SET. Perfect armed-vs-engaged separation.
//   UNITS: correlated against the calibrated speed (D1:D2) during stable holds:
//       D5=16 -> measured 17.4 km/h
//       D5=18 -> measured 18.9 km/h
//       D5=21 -> measured 20.7 km/h
//   i.e. D5 tracks the held speed in km/h within ~1 km/h. (Two other D5 values,
//   19 and 22, show contaminated medians because they span the ramp-up and the
//   fault/disengage, not steady cruising.)
//   Rider set points were nominally 11/12/13/14/15 mph on the dash; the bike
//   stores the set point metric, consistent with everything else on this bus.
//   *** MODEL RESOLVED *** by a narrated fresh-power-cycle capture
//   (cruisecontrol_set_unsetbybutton_set_unsetbybrake). CRUISE STATE IS THE PAIR
//   (D6 bit7, D5 setpoint), and bit7 means "NOT CURRENTLY CONTROLLING" - it is SET
//   while standing by and CLEAR when either off or actively engaged:
//        bit7=0, sp=0   -> OFF
//        bit7=1, sp=0   -> ARMED (cruise on, no target yet)
//        bit7=0, sp>0   -> ENGAGED, actively holding sp km/h
//        bit7=1, sp>0   -> CANCELLED with target RETAINED (resume available)
//   OBSERVED SEQUENCE (percent of that capture):
//        22.8%  bit7 0->1, sp 0       ARM
//        31.9%  bit7 1->0, sp 0->20   SET / engage at 20 km/h
//        42.1%  bit7 0,    sp 20->0   CANCEL BY BUTTON - setpoint CLEARED
//        58.0%  bit7 0->1, sp 0       ARM again
//        64.7%  bit7 1->0, sp 0->17   SET / engage at 17 km/h
//        76.3%  bit7 0->1, sp stays 17  CANCEL BY BRAKE - setpoint RETAINED
//   *** THE TWO CANCEL METHODS DIFFER ***: the button clears the stored target,
//   the brake keeps it for resume. That is standard cruise behaviour and it also
//   EXPLAINS the earlier apparent contradiction - the cruisecontrol_92f capture
//   simply started mid-session with a setpoint left over from a previous brake
//   cancel, so D5 was non-zero before bit7 ever set.
// [CONFIRMED] 0x160 D6 bit7 (0x80) = CRUISE CONTROL ARMED (enabled, not engaged).
//   0x09/0x05 base -> 0x89/0x85 when cruise is switched ON.
//   Isolated with cruisecontrol_3x_onoff: exactly 3 contiguous pulses matching the
//   3 arm/hold/disarm cycles, and bit7 is set in 50% of that capture's frames.
//   CROSS-CHECKED AGAINST ALL 34 OTHER CAPTURES: bit7 is set in 0% of every single
//   one. No false positives anywhere. This is arm/enable state only - the SET/
//   engage state (actively holding a speed) is a separate, still-unmapped signal.
//   Other bits of D6 (0,2,3) vary independently (base values 0x05 vs 0x09).
// D7=rolling counter(0-63), D8=checksum (ignore).
// NOTE: 0x160 D4 also carried a small high-beam-linked change in one capture;
//   treat D3:D4 decode as [STRONG] not [CONFIRMED].
// ---- 0x162 (354) : energy-flow direction / mode + kickstand -----------------
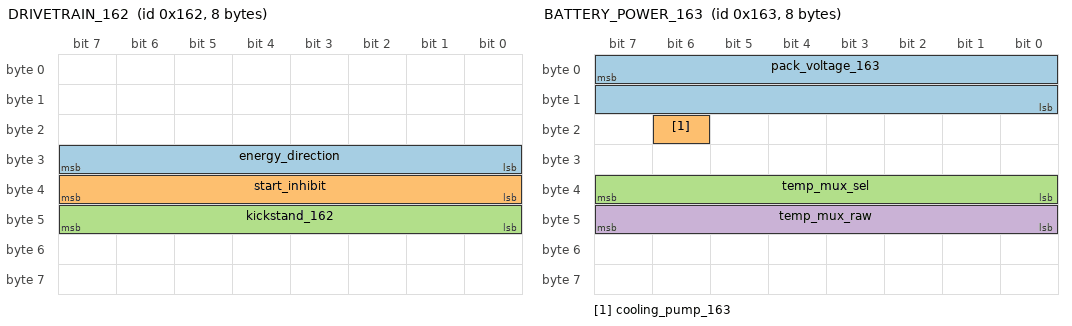
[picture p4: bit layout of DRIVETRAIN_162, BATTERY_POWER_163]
BO_ 354 DRIVETRAIN_162: 8 Vector__XXX
 SG_ energy_direction : 31|8@0+ (1,0) [0|255] "" Vector__XXX
 SG_ start_inhibit    : 39|8@0+ (1,0) [0|255] "" Vector__XXX
 SG_ kickstand_162    : 47|8@0+ (1,0) [0|255] "" Vector__XXX

// VAL_ 0xC8=down 0xA8=up 0x28=up+motor_ready
// [CONFIRMED] 0x162 D4 = NIBBLE-PACKED drive state + energy flow:
//   HIGH nibble = drive-enable state:  0x4_ = MOTOR ENABLED,  0x8_ = NOT enabled.
//     Verified across the full sequence: 0x81 while ign-on-but-motor-off, during
//     ENABLING, during DISABLING and when off; 0x41 for the entire motor-enabled
//     period (ready, rolling, braking).
//   LOW nibble = energy-flow / load detail (0x_1 rest, 0x_2 driving, 0x_6 regen
//     seen in earlier captures). Treat low nibble as [STRONG], high nibble as
//     [CONFIRMED].
// [CONFIRMED] 0x162 D5 = START-INHIBIT BITFIELD (each bit = one reason the bike
//   will refuse to enable the motor; the cluster reads these to choose which
//   message to display, e.g. "UNLOCK FORK LOCK"):
//     bit1 (0x02) = KICKSTAND DOWN.  Verified against the independent kickstand
//        byte (D6, 0xC8=down / 0xA8=up): 100 % agreement in 43 of 44 captures.
//        The only exception is test.csv (73 %), which is the boot capture full of
//        0xFF invalid values - i.e. not a real disagreement.
//     bit2 (0x04) = FORK LOCK ENGAGED (see below).
//   *** BITFIELD MODEL CONFIRMED *** A dedicated capture stepping through all four
//   combinations produced exactly: 0x00 (neither), 0x02 (kickstand only),
//   0x04 (fork lock only), and 0x06 (BOTH asserted simultaneously). Independent
//   reason bits, not a priority-encoded enum. This retroactively validates reading
//   the multi-bit values (0x0A, 0x22, 0x28, 0x2A, 0xA8, 0xAA) as several inhibits
//   asserted at once.
//   DISPLAY vs BUS: the rider reports the dash always shows the FORK LOCK message
//   when both apply. So the BUS carries the complete state (both bits) while the
//   CLUSTER applies precedence to choose one message. Do not infer bus state from
//   the dash text - the dash is lossy by design.
//
//     bit0 (0x01) = THROTTLE NOT AT ZERO  [STRONG]. Set for the whole period the
//        rider held the throttle open (17-72 % of throttle_inhibit.csv, 54 % of
//        frames) and essentially absent from all 45 other captures. A START press
//        during that window was refused (0x133 D1: 0x60 -> 0x80 -> 0x60), so it
//        behaves as an inhibit. Slightly weaker than the kickstand/fork evidence
//        because it was one continuous hold rather than 3 separate pulses.
//   NOTE: THROTTLE POSITION ITSELF IS NOT ON SECONDARY. No byte anywhere differed
//     between throttle-held and throttle-closed. This is expected: per the EDM the
//     Twist Grip Sensor [204]/[224] wires into the RHCM, and the RHCM is a PRIMARY
//     bus module. Only the binary "throttle not zero" inhibit is gatewayed here.
//   BITS OBSERVED IN USE BUT NOT YET IDENTIFIED: bit3 (0x08),
//     bit5 (0x20), bit7 (0x80). Bits 3/5/7 only appear during ignition and boot
//     captures, so they are plausibly "system not ready" inhibits that clear once
//     initialisation completes. Observed combined values: 0x0A, 0x22, 0x28, 0x2A,
//     0xA8, 0xA9, 0xAA - i.e. several inhibits can be asserted simultaneously.
//   *** CHARGING INHIBIT: NO BIT IS SET, AND NO START IS ATTEMPTED ***
//     A capture with the bike CHARGING and START pressed shows 0x162 D5 = 0x00 for
//     the entire capture AND 0x133 D1 with ZERO transitions (stays 0x50 CHARGING).
//     This is a DIFFERENT refusal mechanism from fork lock / kickstand / throttle:
//       - those set an inhibit bit AND show an attempted enable (0x60->0x80->0x60)
//       - charging shows neither: the START press is ignored outright, the state
//         machine never leaves 0x50.
//     So "cannot start while charging" is enforced by the state machine refusing to
//     leave the CHARGING state, not by the inhibit bitfield. Do not expect a
//     charging bit in 0x162 D5.
//   (earlier note) a 1.1 kW AC charge capture did NOT clearly set a new inhibit bit -
//     0x162 D5 read 0x00 for almost the whole capture, with single stray frames of
//     0x10 and 0x18 (bit4 / bit3|bit4). bit4 (0x10) had never been seen before, so
//     it MAY be charge-related, but one frame is not evidence. NOTE the capture did
//     not include a START press while plugged in, so the charging inhibit was never
//     actually exercised. REDO: plug in, then press START 3x and watch D5.
//   CHARGE POWER: still UNCONFIRMED. With two known levels (1.1 kW and 1.4 kW,
//     ratio 1.273) the best byte-aligned candidate is 0x1A7 D4: 168 -> 216
//     (ratio 1.286). Plausible but NOT confirmed - two points cannot separate scale
//     from offset, and no clean unit fits (implies ~160 counts/kW, or ~18.5/A at
//     120 V AC, or ~61/A on a 400 V pack). Other candidates (0x164 D3, 0x181 D2)
//     are worse fits and 0x164 is a known multiplexed frame.
//     NEEDED: a THIRD charge power, ideally very different (Level 2 at ~5 kW) to
//     pin the scale. Same lesson as SoC, which needed three points.
//   (earlier note) not found in the first capture: charge power/current. The only fields reading
//     11 (=1.1 kW x10) were 0x3C4 D2 (a known rolling counter) and a noisy 0x126
//     byte - neither survives scrutiny. SoC stayed at 97 % throughout, so the
//     capture was likely too short for charge accumulation to show.
//   REMAINING INHIBITS TO IDENTIFY: bits 3, 5, 7 (ignition/boot only), plus
//     whatever covers charging. Method: create the condition,
//     press START three times, and see which bit is set during the refusals.
//   REFUSAL SIGNATURE: with either bit set, pressing START drives the system state
//   0x133 D1 through 0x60 -> 0x80 (ENABLING) -> 0x60, aborting instead of reaching
//   0xE0 (motor enabled). All 8 attempts in lockedthenstart_2x_kickdownthenstart_2x
//   show this; none reached 0xE0. So a refused start IS observable on the bus.
//   NOTE: there is NO separate "inhibit reason" enum or message channel - the
//   reason is simply which bit is set. The dash message is generated locally from
//   these bits, which is consistent with the cluster also generating the TPMS and
//   ABS/TC warnings itself.
//
// [CONFIRMED] 0x162 D5 bit2 (0x04) = FORK LOCK ENGAGED.
//   0x00 unlocked -> 0x04 locked. Isolated with forklock_3x_5sgap: exactly three
//   contiguous pulses matching the three lock/unlock cycles (49 % of that capture's
//   frames), and bit2 is set in 0 % of all 42 other captures - no false positives.
//   Confirms the EDM's fork lock connector [213] (2-way JAE MX19) is a real sensed
//   input and that its state reaches secondary CAN.
//   NOTE 0x162 D5 is a chassis-status BITFIELD - other bits are in use:
//     bit1 (0x02) appears in kickstand and turn-signal captures (meaning unknown)
//     bit3 (0x08) and bit5 (0x20) appear during ignition transitions
//   Only bit2 is confirmed. Mask it explicitly rather than comparing the whole byte.
//
// [CONFIRMED] 0x162 D6 = kickstand: 0xC8 = DOWN, 0xA8 = UP, 0x28 = UP+motor-ready.
//   Polarity resolved: idle_kickstand_down_freshstartup reads 0xC8 steady (down);
//   kickstand_2xup toggles C8->A8->C8 (up=A8, returns down); 3xup shows 3 A8
//   excursions; ks_up_start_pressed ends at 0x28 (up + motor enabled).
//   (0x181 D4 0xD1<->0xE1 also tracks kickstand but is a shared status byte.)
// ---- 0x163 (355) : BATTERY POWER / ENERGY FLOW (16-step bar) ----------------
BO_ 355 BATTERY_POWER_163: 8 Vector__XXX
 SG_ pack_voltage_163 : 7|16@0+ (0.0625,0) [0|4095] "V" Vector__XXX
 SG_ cooling_pump_163 : 22|1@0+ (1,0) [0|1] "" Vector__XXX
 SG_ temp_mux_sel : 39|8@0+ (1,0) [0|5] "" Vector__XXX
 SG_ temp_mux_raw : 47|8@0+ (1,-40) [-40|215] "degC" Vector__XXX

// [UPDATE 2026-07-27 — ride1 real-timestamp capture + deep review; double-verified.
//  RETRACTS the D2 "16-step battery power bar" (battery_power_level) below.]
//   pack_voltage_163 = (D1:D2) / 16 V  -- a THIRD independent pack-voltage word
//     (agrees with 0x181 pack_voltage and 0x1A7 within ~2.5 V at rest; r 0.91-0.98).
//     WHY THE "BAR" WAS WRONG: legacy captures kept D1 pinned at 0x18, so D2's high
//     nibble alone looked like a 16-step bar ("level 9" = 0x18xx = 393 V rest EMF;
//     "charge levels" = charging voltage rise). ride1's sag drove D1 through
//     {13,14,15,16,17,18} (word 5040->6304 = 315->394 V) with clean byte-carry
//     crossings at the 384 V boundary (0x1810->0x17F0->0x1800) - absurd under a bar.
//   D5/D6 = 6-PHASE TEMPERATURE MUX. temp_mux_sel (D5) cycles 0..5 at 50 Hz (~120 ms
//     revisit). D6 payload, degC = raw-40, is a DIFFERENT channel per selector:
//       sel0 = FAST powertrain temp (inverter/winding-class): ride1 26->81 C through
//              the WOT pull, decaying ~11 C in the 1.1 s coast after (a counter cannot
//              fall). 75mph stand cruise only 68-72 raw. CORPUS MAX 102 C (newcap_5),
//              90 C (newcap_8) - transient spikes carried off by the liquid loop.
//       sel1 = SLOW-MASS temp (motor/coolant-class): ~ambient+2.4 at rest. CORPUS MAX
//              was 42 C on the stand; the STREAMED ROAD RIDES pushed it far higher under
//              sustained load - a clean MONOTONIC heat-soak: 33->42 C (s54 freeway), 42->59 C
//              (s55 record run, +17 C over the old ceiling), 60 C (s57, new streamed max).
//              Still the coolant loop never ran hot enough to trip the 0x1A6 drive fan.
//       sel2-5 = corpus-constant 170/190/170/180 (=130/150/130/140 C) - a plausible
//              limit/derate table, UNEXERCISED (flagged, not decoded).
//     Static regressions across 21 captures: sel1 = 42 + 1.01*ambient (r=0.90),
//     sel0 = 33 + 1.23*ambient (r=0.83) - slope~1, offset~40 confirms the raw-40 scale.
//     *** temp_mux_raw above decodes D6 REGARDLESS of selector - gate on temp_mux_sel
//     before use (sel0/sel1 only). This is the LIVE powertrain temp.
//   *** OPEN THREAD "motor temp on a road ride" RESOLVED HERE [2026-07-29, s54/s55/s57]. ***
//     THIS 0x163 mux IS the motor/inverter temperature: sel1 = motor/coolant-class (33->60 C
//     across the freeway rides), sel0 = inverter/winding-class (streamed rides reconfirmed it,
//     s57 peaked 92 C; legacy corpus max 102 C). It was NEVER on 0x183 D5/D6 - that earlier
//     hypothesis is RETRACTED: 0x183 D5 is the SLOW-MODE / low-SoC power-derate flag (see the
//     0x183 block), and 0x183 D6 is an unexercised spare - neither is a temperature.
//     Absolute-scale/component-ID of the 0x163 mux still wants an IR-thermometer cross-check.
// [CONFIRMED] cooling_pump_163 = 0x163 D3 bit6 (0x40) = MAIN / DRIVE COOLING PUMP ON
//   (wired as a live signal above). 37 (0x25) = off, 73 (0x49) = running. The two states
//   differ in several bits (0x25 vs 0x49); bit6 (0x40) is the clean discriminator (SET in
//   0x49 running, CLEAR in 0x25 off). NOTE: an earlier comment said "bit5 (0x20)" - that
//   was wrong (bit5 is actually SET when OFF, i.e. inverted); validate.py now asserts this.
//   Verified against motor-enabled state (0x133 D1 == 0xE0) across ALL 50 captures:
//   enabled -> 73 without exception; not-enabled -> 37. Only a few single frames
//   differ, at state transitions.
//   Matches the rider's audible report exactly: "the main pump turns on moments
//   after the start button and runs throughout run mode".
//   NOTE it is OFF during charging (0x163 D3 = 37 in every charge capture) - the
//   CHARGER has its own separate circuit, see 0x1A6. The two pumps sound alike but
//   are independently commanded, which is why the rider hears one or the other
//   depending on what the bike is doing.
//   ENCODING CONSISTENCY: the charger's cooling-active flag uses the SAME bit6 in
//   the same 37 (0x25) -> 73 (0x49) pattern on 0x1A6 D3. Two circuits, one convention.
//
// --- SUPERSEDED HISTORICAL DECODE (kept as the research record; do NOT wire) ------
// NAMING: this is BATTERY power, not motor power. It moves during AC charging,
//   which never involves the motor at all, so a motor-centric name would be wrong.
//   Motor-side quantities (phase current, torque command, motor RPM as a control
//   value) are NOT here - the PEU is a PRIMARY-bus module.
// [superseded] 0x163 D2 = BIDIRECTIONAL BATTERY POWER BAR - **quantised**, not raw.
//     level = D2 >> 4     (upper nibble; D2 is ALWAYS a multiple of 16)
//   Every value ever observed across 50 captures: 0x00,0x10,0x20 ... 0xF0 - exactly
//   16 discrete levels, no intermediate values - i.e. it is effectively a 4-BIT
//   field in the upper nibble, with the lower nibble always 0x0.
//   *** IT IS NOT A DASH BAR. *** An earlier note guessed this was the dash
//   power/regen bar; the rider confirms the S2 dash has NO power or regen bar at
//   all. The purpose of the quantisation is UNKNOWN - possibly for the phone app,
//   telematics, or internal energy management. Do not infer a consumer from it.
//     level 9  (0x90 = 144) = ZERO flow
//     levels 10-15 (0xA0..0xF0) = energy INTO the battery  (6 steps)
//     levels 0-8   (0x00..0x80) = energy OUT of the battery (9 steps)
//   COVERS BOTH DIRECTIONS INCLUDING AC CHARGING: during a charge ramp it stepped
//   144 -> 160 -> 176 -> 192 as charge power rose 0 -> ~1.3 kW (cross-referenced
//   against the calibrated 0x1A7 D2 charge power). So it is a true battery-IO
//   indicator, not motor-only - it is the one signal that spans charge AND discharge.
//   CALIBRATION IS NOT LINEAR ACROSS DIRECTIONS - do not extrapolate:
//     charge side: ~0.43 kW per level near zero (3 levels for ~1.3 kW)
//     discharge side: only 9 levels exist, yet the bike makes 63 kW peak. At the
//     charge-side scale that would cap at ~3.9 kW, which is obviously wrong. So the
//     discharge scale is much coarser and/or non-linear (likely a display curve).
//   FOR CONTINUOUS MOTOR LOAD USE 0x161 D2/D4 INSTEAD (see that block) - it is the
//   high-resolution analog. 0x163 remains the only field covering CHARGING too.
//   PRACTICAL USE: treat it as a 4-bit level for LEDs/telemetry - direction and
//   relative intensity are reliable, absolute watts are NOT recoverable from it.
//   (Supersedes two earlier errors: (a) describing it as a CONTINUOUS signed power
//   value - direction and centre were right, continuity was not; and (b) calling it
//   the dash power/regen bar - the dash has no such display.)
// ---- 0x181 (385) : BATTERY / HV STATUS --------------------------------------
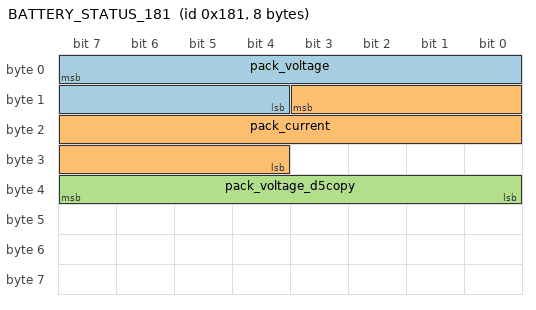
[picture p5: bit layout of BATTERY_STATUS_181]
BO_ 385 BATTERY_STATUS_181: 8 Vector__XXX
 SG_ pack_voltage : 7|12@0+ (1,0) [0|4095] "V" Vector__XXX
 SG_ pack_current : 11|16@0+ (0.1,-400) [-400|6153.5] "A" Vector__XXX
 SG_ pack_voltage_d5copy : 39|8@0+ (1,256) [256|511] "V" Vector__XXX

// [STRONG - NEW 2026-07-28] pairing_status (D1:D3) = the TCU broadcasting whether the bike
//   is LINKED to a phone-app / cloud account. Captured the exact H-D app "Add Bike" pairing:
//   D1:D3 held 0x000000 for the first 31 s (through standby + kickstand) then flipped to
//   0xAFA9D0 at the instant the app reported SUCCESS, and stayed there. It is 0x000000 in
//   ALL 8 pre-pairing captures (idle/charge/ride/ignition, incl. ks-up+standby) across
//   different sessions - so no ordinary vehicle state produces it; it tracks ACCOUNT-LINK.
//   The pairing itself is OFF-BUS: no UDS/SecurityAccess on secondary, and the displayed
//   pairing code (e.g. 719517) appears in NO frame in any encoding - only this status flag
//   surfaces on the bus. *** OPEN: three candidate meanings, separable by two controlled
//   variables (power-cycle, app-open): (a) NVM "account-paired" flag - non-zero forever once
//   paired, survives restart with the app closed; (b) "cloud-link-active" - set whenever the
//   TCU has a live cellular link to the H-D backend; (c) "app actively connected" - set only
//   while the phone app is open and talking to the bike. [UPDATE 2026-07-28] SURVIVES A POWER
//   CYCLE: a post-reboot capture reads 0xAFA9D0 from its first frame. (c) is RULED OUT: the
//   value is identical with the app backgrounded, force-refreshed to the FOREGROUND, and after
//   reboot - app state does not affect it. The value is CONSTANT 0xAFA9D0 across ALL captures
//   (pairing / same-session / post-reboot / app-fg) = a status MARKER / stable identifier, NOT
//   a per-session token or a timestamp (0xAFA9D0=11512272 fits no time base and never changes).
//   It is NOT a CRC/hash of the VIN or ICCID (checked) -> derived from account/user data not
//   visible to us. CONFOUND on (a) vs (b): the TCU is a telematics module that stays alive
//   across a bike reboot (remote features), so its cloud link almost certainly never dropped -
//   "survives reboot" therefore does NOT separate a stored NVM flag from a persistent cloud
//   link. THE definitive test is UNPAIR the bike from the app: if 0x395 D1:D3 -> 0x000000 it is
//   confirmed the account-link status; a subsequent re-pair tells account-derived (same value)
//   vs per-pairing (new value). Leading read: a stable "account-linked" identifier.
//   *** [UPDATE 2026-07-29 — 10-session review] 0x395 D5:D6 = CELLULAR SIGNAL STRENGTH (supersedes
//   the old "slow accumulator-ish field" note AND the retracted 0x395 D5 rotation_latch above):
//   D6 (cellular_signal_395) = fine raw metric 59-199, higher=stronger; D5 hi-nibble = quantized
//   bars 2-6 derived from D6 (D6 mean per level 107/114/125/144; corr(D5hi,D6)=+0.83 global,
//   +0.92..0.95 within-ride). Discriminator: STATIONARY = signal-stable (park/charge D6 span 5-11,
//   D5hi pinned) vs MOVING = signal-volatile (city/freeway D6 span ~100, D5hi sweeps {2..6}) -
//   classic received-signal behaviour, uncorrelated with speed/power/SoC; broadcast ~0.05 Hz (~20 s
//   modem report cadence). [CANDIDATE/PLAUSIBLE] Ground truth = DT-II "TCU Signal Strength" data
//   item (+ a TCU 0x7D4 UDS signal DID); settle the bars=D5hi / higher=stronger polarity in the
//   garage by logging 0x395 while the dash bars change. Only D6 is wired; D5 hi-nibble = derived
//   bars (comment). ***

// ============================================================================
// UDS DIAGNOSTICS - CONFIRMED, observed live on secondary CAN
// ============================================================================
// The instrument cluster's own Diagnostics screen POLLS every module over UDS on
// this bus. Capturing that screen (diagnostics_listing.csv) gave confirmed module
// addresses because the responses matched the dash readout exactly.
//
// SERVICES OBSERVED IN USE BY THE DASH:
//   0x19 01 05   ReadDTCInformation / reportNumberOfDTCByStatusMask
//                response 0x59 01 <mask> <fmt> <countHi> <countLo>
//   0x22 F1EE    ReadDataByIdentifier - module ID / part number (ASCII, ISO-TP
//                multi-frame). This DID is CONFIRMED WORKING on this vehicle.
//
// ADDRESSING: standard UDS, response ID = request ID + 8.
//   Requests were sent to: 0x7E0, 0x7E2, 0x7E3, 0x7E4, 0x7E5, 0x7E6, 0x7E7,
//                          0x7D3, 0x7D4, 0x7F0, 0x790
//
// ============================================================================
// *** MODULE MAP - RESOLVED 2026-07-27c (active UDS sweep of all 9 modules) ***
//   Read this table; the derivation blocks below are the historical record of how
//   each address was pinned (kept for provenance, NOT open questions any more).
//     req / resp      module   basis
//     0x7E2 / 0x7EA   BCM      DTC_COUNT=3 == dash "BCM 3"; F191 41001171A
//     0x7E3 / 0x7EB   LHCM     DTC_COUNT=2 == dash "LHCM 2"; part 0819112-0010; VIN
//     0x7E4 / 0x7EC   VSC      F193 part 41001094A2 == H-D DT-II release notes; logs
//                              powertrain P-codes, monitors ABS+IMU. Double-locked.
//     0x7E5 / 0x7ED   RHCM     part 0812837-0010 / 813636-0066 adjacent to LHCM parts
//     0x7E6 / 0x7EE   RESS     per-cell voltage array on DIDs 0205/0210 (mV) - only
//                              the battery has that. F193 66000297.
//     0x7E7 / 0x7EF   EHCU     F1EE -> "40800178" == dash "EHCU 0 ID#40800178"
//     0x7D3 / 0x7DB   OBC/HV   4-ch sensor cluster 0200/0210; lifetime counter FEE0;
//                              F193 41001111A5 (shares VSC's 41001 HV-supplier family)
//     0x7D4 / 0x7DC   TCU      TELEMATICS - eSIM ICCID (0298), LIVE GPS position (0200,
//                              2x float32 lat/lon; multi-session track across the 2026-07-28
//                              burst, NOT a stored fix), LIVE serving PLMN (0296, DYNAMIC:
//                              Verizon <home-PLMN-redacted> @ s6 -> T-Mobile 310/260 across the burst, two
//                              searching->register transitions). CONFIRMED - see uds_data_map.md.
//     0x7F0 / 0x7F8   ID-only  identification-only ECU: F1E8/F1EB.. IDs, NO data
//                              (FDxx/FExx) blocks. Not the TCU; purpose = ID responder.
//   SILENT (no module): 0x790, 0x7E0 (and bench guesses 0x7E1,0x7D0,0x7D1,0x7D2).
//   IMU is NOT a UDS responder - it has no diagnostic address; it is monitored by
//   the VSC (0x7E4), which logs its lost-comms DTCs. Do not look for a 0x7Ex IMU.
//   *** [OEM MANUAL CROSS-CHECK 2026-07-29 — HD Electrical Diagnostic Manual via DT-II HD-48650] ***
//   The factory manual is organised by FUNCTION, not by ECU, and NEVER exposes UDS addresses/SIDs/
//   DIDs (it's a DT-II tool manual) - so it does not contradict this address map; the addresses are
//   OUR discovery. Its module-ownership rule DOES refine the roster:
//     - VSC is NOT a separate module - it is the SUPERVISORY FUNCTION of the PEU ("PEU/VSC"). 0x7E4
//       is that unit's secondary-bus face; the PEU/inverter (primary bus) is the SAME physical ECU.
//     - OBC stores no own DTCs -> codes appear as "PEU/OBC" (matches 0x7D3 above).
//     - LHCM / RHCM / IMU store NO DTCs (they answer UDS ID but hold no fault memory) - confirms the
//       IMU note above and the switch-pod nature of LHCM/RHCM.
//     - DTC-STORING modules per the manual: ABS(EHCU), BCM, IM, PEU/VSC, RESS, TCU.
//   The manual's U-code routing table independently CONFIRMS this inventory from the OEM side:
//     U0121->EHCU, U0125->IMU, U0156->IM, U0140->BCM, U0141->LHCM, U0142->RHCM, U0198->TCU,
//     U019B->PEU/OBC, U01A1-5->RESS, U0293->PEU/VSC. Codes are 7-char (5 base + 2 Failure-Type Byte).
//   Full DTC catalogue + FTB decode + routing table: docs/livewire_s2_DTC_reference.md.
//   *** [ROUND-4 2026-07-28] "9 modules" is a FLOOR, not a ceiling. ***
//   A 10th diagnostic responder exists: ID 0x6E6 is NOT a periodic frame but an ISO-TP/
//   UDS RESPONSE channel (carries 59 02 ReadDTC, multi-frame 62 F1 80/81/93 ReadDID, and
//   7F NRCs) whose REQUEST id 0x6DE never appears on secondary -> a gatewayed/internal H-D
//   diagnostic address OUTSIDE the mapped nine. Also 0x7F2 is a UDS request to a further
//   unmapped module. So the map is "9 mapped + >=1 more (req 0x6DE / resp 0x6E6) + 0x7F2".
//   [LIVE 2026-07-28] Actively sending 0x22/0x19 to 0x6DE and 0x7F2 gets NO response - they
//   are PASSIVE-only (an internal module-to-module diagnostic exchange we overhear, not one
//   we can elicit from the DLC tap). So 0x6E6 is real but not reachable by us actively.
// ============================================================================
//
// MODULE MAP (historical derivation - passive DTC/ID pass, superseded by the table above):
//     0x7D3 / 0x7DB    (0 DTCs)
//     0x7D4 / 0x7DC    (0 DTCs)
//     0x7E2 / 0x7EA  = BCM    CONFIRMED - returned DTC_COUNT=3, dash "BCM 3"
//     0x7E3 / 0x7EB  = LHCM   CONFIRMED - returned DTC_COUNT=2, dash "LHCM 2"
//     0x7E4 / 0x7EC    (0 DTCs)
//     0x7E5 / 0x7ED    (0 DTCs)
//     0x7E6 / 0x7EE    (0 DTCs)
//     0x7E7 / 0x7EF  = EHCU   CONFIRMED - 0x22 F1EE -> ASCII "40800178",
//                             dash "EHCU 0 ID#40800178"
//     0x7F0 / 0x7F8    (0 DTCs)
//   Addresses polled but SILENT (no module present): 0x790, 0x7E0
//   The dash lists 10 modules but INST1 is the cluster ITSELF - it knows its own
//   ID locally and is never polled over CAN, which is why "INST1 ID#70901105"
//   never appears on the bus. 10 listed - 1 local = 9 remote = 9 responders. Tidy.
//   REMAINING 5 (IMU, RHCM, TCU, RESS, OBC) - the inference chain, now all RESOLVED
//   above (kept to show the reasoning; the "?" and "CONFIRM" tags are closed):
//     0x7E4/EC = VSC        CONFIRMED. Captured F193 part '41001094A2' == the VSC
//                           part '41001094A2D' in the H-D Digital Technician II
//                           release notes; also logs the powertrain P-codes and
//                           monitors ABS+IMU (see DTC section). Double-locked.
//     0x7E5/ED = RHCM       HIGH. Part nums 0812837-0010 / 813636-0066 are the exact
//                           FORMAT and adjacent to confirmed LHCM (0819112-0010 /
//                           813635-0044) - left/right hand modules are sequential parts.
//     0x7E6/EE = RESS       *** CONFIRMED 2026-07-27b (ACTIVE UDS) *** Read its 0x02xx
//                           block live: DIDs 0205/0210 return a long list of per-cell
//                           voltages in mV (0F9E/0F9D/0F9F.. = 3997-4005 mV), i.e. the
//                           full pack cell array - only the battery has that. Was RESS?.
//     0x7D3/DB = OBC?       LOW-MOD. F193 '41001111A5' shares VSC's 41001 HV-supplier
//                           family, so an HV/powertrain box (charger or RESS). NEEDS CONFIRM.
//     0x7F0/F8 = ?          LOW. Distinct DID set: F1E8='32700101', F1F5 part
//                           '6016139-0020', F1EB/EC/ED=170/130/340, no standard IDs.
//                           NOT the TCU (no cellular/telematics data seen). CONFIRM.
//     0x7D4/DC = ?          F191 hardware '41001221' (41001 HV family, NOT the IMU as
//                           earlier guessed), serial '<serial-redacted>', F193 sw 'B1.2'.
//                           An HV/powertrain box (PEU/motor-inverter candidate). CONFIRM.
// *** UPDATE 2026-07-27b - ACTIVE UDS now WORKS (firmware Diagnostics mode, driven over
//   the LAN). All 9 addresses {7E2,7E3,7E4,7E5,7E6,7E7,7D3,7D4,7F0} answer; the bench
//   guesses {7E0,7E1,7D0,7D1,7D2} are silent. Active reads MATCH every passive serial/
//   part above (tool validated end-to-end). NEW: identification uses F191 (hardware #),
//   NOT F187 (which returns NRC 0x31); captured F191 = 7E2:41001171A, 7E3:71500536A(+VIN),
//   7E5:71500541, 7D4:41001221; F18B mfg dates and F195 sw versions for all. ***
// *** UPDATE 2026-07-27c - FULL DATA-DID SWEEP of all 9 modules (284 DIDs) + 9-agent
//   decode. MODULE MAP NOW RESOLVED (see docs/livewire_s2_CAN_uds_data_map.md for the
//   full decoded catalogue). Corrections to the map above:
//     0x7D4 = TCU (TELEMATICS) - CONFIRMED. Exposes the eSIM ICCID (DID 0298), a stored
//             GPS fix (DID 0200, 2x float32 lat/lon), and the serving PLMN (DID 0296 =
//             ASCII "<home-PLMN-redacted>" = MCC <redacted> / MNC <redacted> = Verizon US). *** RETRACTS the "PEU/
//             motor-inverter candidate" guess for 0x7D4. *** (Part 41001221 = integrator
//             prefix, not HV-specific.)
//     0x7D3 = OBC/HV box firmed (internal 4-ch sensor cluster at 0200/0210; lifetime
//             counter FEE0). 0x7F0 = identification-only ECU (no data/FDxx/FExx blocks).
//   *** PLMN GROUND TRUTH for the 0x392 crack: the SIM's home network is MCC <redacted> / MNC
//   <redacted> (Verizon). Note <operator-id-redacted> is NOT a plain 3GPP BCD of <home-PLMN-redacted> (that is <home-PLMN-BCD-redacted>),
//   so 0x392 D2:D3:D4 is an obfuscated/offset PLMN or a different field - solve the
//   transform against this known value.
//   [CORRECTION 2026-07-28] The 0296 SERVING PLMN DIVERGED from the fixed broadcast
//   operator_id <operator-id-redacted> during a REAL carrier switch (Verizon -> T-Mobile 310/260 across
//   the streamed burst) while <operator-id-redacted> stayed put. So <operator-id-redacted> = the SIM HOME-network id
//   (stable), and the crack must be solved against the SIM HOME PLMN (<home-PLMN-redacted> Verizon) -
//   do NOT use the now-changed serving 0296 value as the decode reference for <operator-id-redacted>.
//   IMSI still not in cleartext: it is behind the three LOCKED (0x27) telematics DIDs
//   0283/0285/0289 on 0x7D4, or in the unswept 0299-02AF range next to the ICCID. ***
//   DEFINITIVE METHOD (tap can TX): read F18C/F187 from each address and/or
//      match the dash Diagnostics ID# list to the captured serials. See below.
//   NOTE: dash DISPLAY ORDER does NOT equal poll order. The tester sends requests
//   in ascending CAN-ID (arbitration) order - verified: the 0x22 round went
//   0x790,7D3,7D4,7E0,7E2,7E3,7E4,7E5,7E6,7E7,7F0 = strictly ascending. And the
//   known modules break display order anyway (display: BCM 2nd, EHCU 3rd, LHCM
//   5th; by address: BCM 0x7E2, LHCM 0x7E3, EHCU 0x7E7). So ordering cannot be
//   used to map the remaining six.
//
// DID SUPPORT MATRIX (important):
//   0x22 F1EE is supported ONLY by the EHCU (0x7EF). Every other module answers
//   0x7F 22 31 = NRC 0x31 requestOutOfRange. So F1EE is not a universal ID DID on
//   this vehicle - other modules need different DIDs (try F190 VIN, F187 part
//
// *** WHY THERE IS UDS TRAFFIC DURING NORMAL OPERATION ***
//   It is NOT tied to diagnostics or to the keyless code start. Identification-DID
//   polling appears in most captures - 39 in a normal boot, 71 in the ABS self-test
//   capture, 34 in the tyre-pressure capture, 30 in the no-fob code start - and
//   recurs in BURSTS during a long run (at ~17 % and ~91 % of a 5-minute capture).
//   MOST LIKELY PURPOSE: module inventory for OTA UPDATES. The S2 is LiveWire's
//   first bike with over-the-air updates, and the TCU needs each module's part and
//   software numbers to decide what updates apply. F18C/F191/F193/F1EC/F1FB are
//   exactly the DIDs for that.
//
// *** DID LIST HARVESTED FROM THE BIKE'S OWN TRAFFIC (better than blind scanning) ***
//   The bike also polls NON-identification DIDs. These are live-data candidates and
//   are known-good because the vehicle itself requests them:
//     0x7EE : 0x0256, 0x025A, 0x025B, 0x025C, 0x025E, 0x025F, 0x0263, 0x0264,
//             0x0269, 0x0270, 0x020E     <- a whole 0x02xx family, i.e. this module
//                                           is being read for a live data block
//     0x7EA (BCM)  : 0x1001            -> 33 09 97
//     0x7EC        : 0x0205            -> 00 48 24
//     0x7EF (EHCU) : 0x0151            -> ASCII 'RGC'
//   START ANY UDS EXPLORATION HERE rather than scanning blindly - these are DIDs the
//   vehicle demonstrably supports.
//
//
// *** MODULE IDENTIFICATION DATA CAPTURED (startup_nofob_codestart_13131) ***
//   During a no-fob / code-entry startup the IM polled identification DIDs from all
//   modules. THE OTHER MODULES DO NOT SUPPORT F1EE - they answer F18C, F191, F193,
//   F1EC, F1FB (0x7F8 uses F1E8/F1EB/F1EC/F1ED). That is exactly why the earlier
//   F1EE-only scan returned nothing but the EHCU.
//   CAPTURED IDs:
//     0x7DB (req 0x7D3): F18C serial '<serial-redacted>'  F193 supplier '41001111A5'
//     0x7EB (req 0x7E3): F1EC '0819112-0010'  F1FB '813635-0044'      = LHCM
//     0x7EC (req 0x7E4): F18C serial '<serial-redacted>'  F193 '41001094A2'
//     0x7ED (req 0x7E5): F1EC '0812837-0010'  F1FB '813636-0066'
//                        F18C '<serial-redacted>'  F191 hardware '71500541541'
//     0x7EE (req 0x7E6): F18C serial '<serial-redacted>'  F193 supplier '66000297'
//     0x7F8 (req 0x7F0): F1E8 '32700101'  F1EB '170'  F1EC '130'  F1ED '340'
//   INFERENCE: 0x7ED is very likely the RHCM. Its part numbers (0812837-0010 /
//   813636-0066) share the exact FORMAT and ADJACENT NUMBERING with the CONFIRMED
//   LHCM at 0x7EB (0819112-0010 / 813635-0044) - left and right hand control
//   modules would be sequential parts from one supplier.
//   0x7DB and 0x7EC share a supplier-code format (41001111A5 / 41001094A2), so they
//   are probably a related pair from one vendor.
//   TO FINISH THE MAP: read these DIDs with the dash Diagnostics page open and match
//   each returned ID against the on-screen module list.
//
//   number, F189 software version, F18C serial).
//   EHCU also emits NRC 0x78 (responsePending) before its real answer - a normal
//   "wait, working on it" and a sign it does real work for the request.
//
// OBSERVED CHANGE BETWEEN CAPTURES: LHCM DTC count went 2 -> 3 between the two
//   diagnostics captures. Something logged a new fault in between (plausibly all
//   the wheel-spinning / ABS self-test activity). Useful: DTC counts are live.
//
// ============================================================================
// DECODING FULL DTCs (fault codes) FROM A PASSIVE CAPTURE
// ============================================================================
//   Beyond DTC *counts* (0x19 01), the bike also runs the FULL read - service
//   0x19 sub 0x02 (reportDTCByStatusMask) - and we can decode the actual codes
//   from a capture WITHOUT sending anything. Proven on faulted_IMoff_restarted.csv.
//   Tooling: `python3 validate.py --dtc CAPTURE.csv`.
//
//   REQUEST : <req_addr>  03 19 02 <statusMask>     (mask 0x09 = confirmed|failing)
//   RESPONSE: <req+8>      59 02 <availMask> then N x 4-byte records, ISO-TP framed:
//     ISO-TP PCI on byte D1:  0x_0 single-frame (len=low nibble),
//                             0x1_ first-frame (len=(nibble<<8)|D2),
//                             0x2_ consecutive-frame (seq=low nibble).
//     Each 4-byte record = [b0 b1]=DTC, [b2]=failure-type byte, [b3]=statusOfDTC.
//       letter = top 2 bits of b0: 00=P 01=C 10=B 11=U ; code = low14 bits as 4 hex.
//       status bits (ISO14229): 0x08 confirmed, 0x20 failedSinceClear,
//                               0x80 warningIndicatorRequested (lit a lamp), 0x01 failing now.
//     Negative resp 0x7F 19 78 = responsePending (module busy/booting - normal).
//
//   *** ONLY these SAE-standard codes are confident; the rest are LiveWire-proprietary
//   (target inferred from SAE norms, may be reassigned): ***
//     U0001 High-Speed CAN Bus | U0121 Lost Comm ABS Module | U0125 Lost Comm
//     Multi-axis Accel Sensor (=our 6-axis IMU) | U0155/U0156 Lost Comm Instrument
//     Cluster/Info-Center (=the IM) | P0560 System Voltage.
//
//   FAULT EVENT DECODED (faulted_IMoff_restarted, rider tripped it via RH controls;
//   IM went dark, bus stayed alive, hand-restarted). The scan's fingerprint:
//     - U0156 logged by 4 modules (BCM, LHCM, EHCU, VSC) = everyone lost THE IM.
//     - VSC also logged U0121 (lost ABS) + U0125 (lost IMU) + P0560 System Voltage.
//     - U0001 CAN-bus fault. => a brief POWER/VOLTAGE brownout dropped nodes off the
//       live bus. NOT an idle timeout (a timeout stores nothing and triggers no scan).
//     - EHCU C1021 carried status 0x88 (warningIndicatorRequested) - a lamp-lighting
//       chassis fault, a plausible source of a dash warning triangle.
//
// *** MODULE MAP EXTENDED: 0x7E4/0x7EC = VSC (Vehicle Supervisory Controller). ***
//   Three-way convergence: (1) its F193 part number '41001094A2' (line above) matches
//   the VSC part (41001094A2D) in the H-D Digital Technician II release notes; (2) in
//   the fault scan 0x7E4 is the module logging POWERTRAIN P-codes (P0560/P1100); (3) it
//   is the module that monitors ABS + IMU comms (U0121/U0125) - exactly a supervisory
//   controller's scope. So of the six unmapped modules, VSC = 0x7E4/0x7EC is now solid.
//   (Digital Technician II is H-D's dealer tool - it DOES support the S2DM: authenticated
//   DTC read/clear with official code text, live-data PID lists, actuator tests, and
//   reflash. It has the OEM DTC-description table we lack - the thing that would name the
//   proprietary U1xxx/C1xxx/B-codes above. Our edge: passive, real-time full signal map
//   + we just read these DTCs with NO tool and NO authentication.)
//
// IMPLICATION FOR BMS/MOTOR DATA: UDS is live and working from the DLC, the
//   gateway relays it, and 0x22 is accepted. Reading RESS/PEU data that is NOT
//   broadcast on secondary is therefore a matter of finding the right DIDs at the
//   right address - the transport is proven. Keep to 0x22 reads on a stand.
//
// ============================================================================
// UDS-DERIVED CALIBRATION / CROSS-CHECKS (2026-07-27c, active reads on a stand)
// ============================================================================
//   Newly readable UDS ground truth was used to pin scales the broadcast bus lacked:
//   - TORQUE ZERO-POINT + LIVE TORQUE: VSC (0x7E4) DID 0207 returned a torque/command
//     value that brackets the 0x161 zero anchor - consistent with torque_request/delivered
//     = word minus 5000 (the 5000 offset now has a second, independent witness).
//     [EXPANDED 2026-07-28, moving rides] words @4/@6/@8 (offset 5000) = LIVE applied/
//     requested/delivered torque, CONFIRMED under load on s28 (r=1.0) and s31 (@8 r=0.999,
//     @4 r=0.992). word0 = 0x1ADB = 6875 = +1875 drive clamp; word1 = 0x0EA6 = 3750 = -1250
//     regen clamp (constant defaults). The +/- clamp magnitudes are UNTESTED / NEVER REACHED
//     across the whole s25-s37 burst (peak applied +825 = 44% of +1875 on s28's hardest
//     launch; s31 26%; charge sessions <=2%) - so +/-1875 / -1250 remain UNPROVEN inference,
//     not measured limits. word1 was seen to dynamically tighten -1250 -> -230 under load in
//     s28 ONLY (candidate; s31/s32/s34/s35 held it at the -1250 default).
//   - ROAD SPEED (LIVE, new 2026-07-28): VSC (0x7E4) DID 020C word0 (u16@0, offset 0x8000)
//     = LIVE signed road speed; byte2 = drive-state (0x01 stop / 0x02 move). CONFIRMED r=1.0
//     vs broadcast speed on moving s28/s31; pinned at 0x8000/byte2=01 at standstill across
//     all stationary sessions (s25/s26/s27/s29/s32-s35). (020C was previously ABSENT from
//     the DBC entirely.)
//   - PACK CURRENT (corrected 2026-07-28): RESS (0x7E6) DID 0209 word0 (u16@0) = PACK
//     CURRENT, ~0.26 A/count, offset 1562 counts at 0 A (fit 1562 + 3.84*I); holds
//     OPPOSITE-SIGN across s28 discharge (n=7) and s32/s33/s34/s35 charge - a constant
//     cannot do that. u16@3 (b3:b4) = the 2nd HV current-sense channel "B" (see the CHANNEL-B
//     note just below - it was formerly guessed "instantaneous vs averaged"). 0209 is
//     NOT a pack-voltage reference; the earlier "0209 = pack voltage" reading is dead (an
//     idle-trap concatenation - see the CORRECTION in the CELL_VOLTAGE_182 block, ~L1733).
//     [FULL-ENVELOPE CONFIRM 2026-07-29] The high-rate streamed rides sampled the deep-
//     discharge regime the slow polls missed: word0 = 1562 + 3.888*I, r=0.996, over I -240..+35 A
//     (s54 to -123 A, s55 to -239 A, s57 to -240 A), slope 3.888 identical s55/s57. AIRTIGHT
//     across the full current envelope - the pack-current attribution is now decisive.
//     [CHANNEL-B CONFIRMED 2026-07-29 r1] RESS 0209 u16@3 (b3:b4) = the SECOND HV current-sense
//     channel "B" (OEM prior: two HV current channels A/B, correlation-checked P0B1300 A/B).
//     It is a NARROW-RANGE, HIGH-PRECISION channel with the SAME encoding as word0/channel A
//     (~1562 + 3.888*I): it tracks the wide-range word0 to within ~1-4 counts at steady state
//     (rock-steady +2-count offset in the |I| < ~33 A band) and HARD-SATURATES at raw ~1432
//     (about -33 A) - it clamps to a constant while word0 keeps falling (min word0 = 624 at
//     I = -241 A, s55/s57), so at the WOT-transient extreme word0 reads -58 A while b3:b4 pins
//     at -33 A. A moving-average copy would LAG smoothly there, not CLIP to a constant - so this
//     is a distinct range-limited sensor, not a filtered copy. 0209 is a clean 6-byte
//     SINGLE-FRAME DID (no ISO-TP splice risk), so the reading is splice-immune. Evidence: s55
//     idle 061a/0618, s55 05da/05d7 (-16.5/-17.2 A), 05c5/05c1 (-21.9/-22.9 A); r(word0,pack_i)
//     +0.996/+0.997/+0.993 (s55/s54/s57).
//   - HV 0235 byte5 = COARSE PACK TERMINAL-VOLTAGE byte (~2.55 V/count, b5 ~= 0.39*pack_v).
//     HV/OBC box (0x7D3) DID 0235, byte5. *** DOWNGRADE / RE-ATTRIBUTION 2026-07-29 r1
//     (adversarial QA): this was PROMOTED 2026-07-29 as a "coarse pack/module-CURRENT mirror"
//     (b5 ~= 142 + 0.20*I, r=0.94 s55 / 0.91 s57) - that label was a LOAD-SAG-TRAP ARTIFACT and
//     is RETRACTED. Under load, terminal V and current move together, so a voltage byte fakes a
//     current correlation. The discriminator is fitting b5 against BOTH and comparing
//     slope-stability: pooled over s28+s44+s54+s55+s57 (n=62) r(b5,pack_v)=+0.999 vs
//     r(b5,pack_i)=+0.850 - voltage wins decisively, AND the voltage-model slope is SESSION-STABLE
//     (0.34-0.45 ct/V) while the current-model slope WANDERS 3x (0.065->0.218 ct/A), the signature
//     of a true line vs a coincidence. So b5 = a coarse pack TERMINAL-VOLTAGE byte, NOT current.
//     (The genuine coarse/fine current channels are RESS 0209 word0/channel-B above; 0235 b3:b4
//     is the separate DC-link voltage node.) *** [METHODOLOGY: before labeling a byte "current",
//     also fit it vs voltage/SoC and require the winning model's slope to be session-stable.] ***
//   - PACK-VOLTAGE REFERENCE: RESS (0x7E6) DID 021F (~1 V/count) matched broadcast pack_v
//     to +/-1 V across s25/s26/s28/s29/s31/s32/s33/s34/s35 (range 365-395 V, discharge +
//     charge), plus VSC (0x7E4) DID 0220 - THESE, not 0209, confirm the 0x181/0x163 pack-V
//     scale (0.0625 V/count on 0x163, 1 V/count on 0x181) against a BMS-internal value.
//   - STATE OF CHARGE (corrected 2026-07-28): RESS DID 0213 = ~88.3% is INTERNAL FINE
//     SoC/SoE in 0.01% - it RISES on charge (8825->8869), so it is NOT SoH (SoH cannot
//     rise intra-session). The SoH-like reference is RESS DID 020E (pinned ~97% while real
//     display-SoC was ~83%). The 0x227x fine-SoC value is replicated across >=6 DIDs. The
//     broadcast display-SoC is on 0x185; a slow secondary byte matching 0213 is not pinned.
//     [STREAMED-RIDE CONFIRM 2026-07-28] 0213 is now confirmed LOAD-RESPONSIVE: it dips on
//     discharge (s28 r=0.97 vs pack_i n=19; s31 r=0.99) and rises on charge (s32/s33/s34/
//     s35) => voltage-instantaneous INTERNAL SoC%, sitting ~18-22 pts ABOVE the broadcast
//     display-SoC 0x185 (s25: 87.2% vs 69%). Reinforces "NOT display SoC, NOT SoH."
//   - CELL ARRAY: RESS DIDs 0205 / 0210 return the per-cell mV list - the same quantity 0x182
//     broadcasts as min/max/avg. The mapper's copy is TRUNCATED at its 46-byte hex cap (23 of
//     ~96 cells; 3997-4005 mV pre-charge), and 0205 was never in a STREAMED poll list, so the
//     full array is NOT yet captured. The stream path DOES reassemble full ISO-TP untruncated
//     (proven: RESS 025E returned 99 words, 0256 100 words), so one full 0205 read = every cell
//     voltage + a direct series COUNT. DONE (s25): full 0205 = 96 words = 96 CELLS (avg 3879 mV,
//     spread 5 mV, sum 372.4 V; cells are DIRECTION-RESPONSIVE - sag on discharge s28/s31,
//     rise on charge s32-s35). [CORRECTED 2026-07-28: the "0209 stayed 400.106 = rated-max
//     96x4.168 -> confirmed constant" clause that stood here was WRONG - 0209 word0 is PACK
//     CURRENT, not a rated-max constant; the 400.106 was an idle-trap concatenation. See the
//     CORRECTION at ~L1733-1738.] SERIES COUNT PINNED 96S (see the CELL_VOLTAGE_182 block).
//   - EHCU ABS BLOCKS RESOLVED 2026-07-28 (streamed moving rides s28/s31, real timestamps):
//     020F (4 B) = DUAL PER-WHEEL SPEED, u16@0 = FRONT, u16@2 = REAR, 0/0 at standstill,
//     r=1.000 vs broadcast 0x326 wheel_speed_front/rear; scale ~25x the 0x326 raw count
//     (~250 counts/km/h, ~0.004 km/h/count); REAR only ever LEADS FRONT (+256 quanta, ~2-4%
//     under power = mild TC-active slip; NO burnout captured). 0212 (8 B) u16@4 = FRONT-BRAKE
//     PRESSURE, r=1.0/0.999 vs broadcast front-brake (0x15A) on s28/s31 (range 0->415). [SCALE
//     REFINED s44 2026-07-28: NOT 1:1 - broadcast ~= 1.214*0212 + 14, i.e. 0212 ~= 0.79x
//     broadcast, r=0.999 over the wide 0->2241 range; same physical quantity, two scaled
//     encodings - the prior s22/s28 "identity" is refined to a 0.79 scale factor. 0212's slow
//     poll capped at 1461 ct, missing the 2241 broadcast peak.] Other words const 0; byte5/6
//     low nibble steps 0/2/4/6 = candidate parked brake-lever position/state; absolute pressure
//     scale still open (no bar/psi reference). 0210 (5 B) byte1 = BRAKE-ACTIVE flag (0->1 on a
//     press, s29), 0 on zero-brake. 0200/0211 = 12 V aux rail (~14 V, 0xAE=174), NOT a wake/
//     ignition counter. CANDIDATE validate.py oracle: EHCU 020F u16@0/@2 / 25 ~= broadcast
//     0x326 front/rear (s28/s31 now log UDS + broadcast simultaneously). CAVEAT: EHCU 021B
//     (ABS op/event counters) returned NRC/no-response to the streamed 191-DID poll in s26 -
//     its decode rests on the single earlier active-sweep read only.
//   - THROTTLE / TWIST-GRIP (CONFIRMED 2026-07-28, cross-session s28+s44): VSC (0x7E4) DID
//     0205 byte0 = LIVE throttle / twist-grip position, b0 ~= 2.7x throttle% (2.55x s28 /
//     2.64-2.75x s44), ZERO-ANCHORED (b0=0 whenever throttle=0; 2 anchors s44). Distinct field
//     within the VSC 0205 per-channel array (NOT the RESS 0205 cell array - a different module).
//     s44 moving throttle sweep: r=1.000, n=6 => promoted from candidate. Raw grip counts are
//     NOT on secondary CAN (nearest broadcast is 0x161 throttle%).
//   - LONGITUDINAL ACCEL / TRACTION-DEMAND (CONFIRMED 2026-07-28 w/ caveat, s28+s44): BCM
//     (0x7E2) DID 0202 byte8 = longitudinal accel / net drive-demand; s28 r=0.93 vs long_g
//     (n=413); s44 r(b8,acc_lon)=0.931, r(b8,torque_del)=0.943 (n=256). Byte oscillates ~78-129,
//     rest-anchor ~106 (=0 g) on charge (r~=0 vs pack current => rules out battery/thermal).
//     CAVEAT: accel and drive-torque are COLLINEAR on a bike, so accel-vs-demand is not fully
//     separable (b8 fits the smooth underlying axis better than the noisy raw acc_lon). Distinct
//     from the replicated 4/3/1/3/1 ADC-group words in the same DID.
//   - CHARGER / OBC BOX 0x7D3 RESOLVED 2026-07-28 (the s32-s48 external charge run first woke
//     these DIDs - they are dark except during AC charge): DID 0232 = CHARGER/PLUG-STATE word,
//     00 00 02 00 whenever NOT taking charge (parked s27, riding s28/s31, AND the mid-charge
//     UNPLUGGED ride s44) vs 02 01 02 02 for the entire duration of charging (s32/s39/s48) -
//     100% separation over 12 sessions; the identical field is mirrored at HV 0200 bytes 8-11.
//     DID 0209 = FF + charge-current byte (byte1 = 0x00 not-charging / 0x4F=79 at CC ~11 A /
//     0x24=36 at CV taper ~4 A); FE10 and FEE1 carry the SAME body (FE10 = FF-prefix, FEE1 =
//     00-prefix) with a trailing 16-bit charge-magnitude word (0xB710 @~11 A -> 0x6B62 @~4 A);
//     zero-at-not-charging + A/B (s44 unplugged = 0) => charge-current/charge-power indicator,
//     absolute A-scale open. This REFRAMES the prior "FE10/FEE1 not a coulomb accumulator"
//     refutation - they ARE a live charge-current register. DID 0201 word@4 (+ the 0200 ~700
//     sensor triplet) = charge-gated CHARGER/OBC TEMP: a thermal ARC ~714-754 (idle/unplugged)
//     -> 885-928 (CC peak) -> COOLS to 821 as CV current tapers (a temp cools when current
//     drops; a voltage/SoC would not) - promotes the "internal sensor cluster, scale suspect";
//     x0.1C-minus-offset scale still open. DID FEE0 is CHARGE-STATE-MULTIPLEXED (~4333 not-
//     charging / ~1520 charging, non-monotonic WITHIN a charge session) - this RETRACTS the
//     "FEE0 = monotonic lifetime op counter" reading and reconciles the doc's own contradiction
//     (the "decrements to ~1523" was the CHARGE state; "increments 4335->4337" was idle - both
//     real, different states). Meaning (time/energy estimate?) still open.
//   - RESS ACCUMULATORS ARE SIGN-BINNED 2026-07-28 (charge run vs s28/s44 discharge rides):
//     025A/025B (20x BE32) split charge vs discharge into SEPARATE dwords - dword@32 (idx8) =
//     cumulative CHARGE-Ah (advances ONLY on charge: s32/s39/s48; FROZEN on discharge rides),
//     while dword@12 (idx3) + dword@72 (idx18) = cumulative DISCHARGE-Ah (advance ONLY on
//     discharge: s28 +10/+37 ct, s44 +11/+43 ct; FROZEN on charge). Mutually-exclusive freezing
//     => not a lone co-trend. This refines the earlier "only idx8 ticks" (that was the charge
//     bucket). A SECOND, distinct accumulator axis: 025C/0269/0270 (120 B = 30x BE32, 4x5
//     zero-delimited buckets) bin by SoC BAND and are SIGN-INDEPENDENT - dword@84 (idx21, lower-
//     SoC bucket) advances on the s28/s31 rides then freezes; dword@88 (idx22, ~90% bucket)
//     advances in BOTH s44 discharge AND s48 charge, with the active bucket handing off idx21->
//     idx22 as SoC crosses ~88-89%. Per-count scale CANDIDATE (small deltas; 120-B DIDs are also
//     ISO-TP-cross-stitch-prone - validated here against clean headers only).
//   - RESS 020D IS A MIN/AVG/MAX ROLLUP, not 9 per-module values (resolves the map's open
//     "per-module min-cell vs temp"): b0=b1=b2=b5=b8 are ALWAYS bit-identical (8/8 sessions) =
//     a repeated coulomb/display-SoC scalar (~1%/ct) that rises 61->95 over the charge and
//     tracks broadcast 0x185 display-SoC (distinct from 0213's voltage-instantaneous fine SoC,
//     which saturates near the top) - this RESOLVES the s28 "0213 87% vs display 67%" gap: 020D
//     is the wide-range coulomb-SoC source, 0213 is voltage-instantaneous. b4 = the 0206 per-
//     cell-metric ARRAY MEAN (matches round(mean(0206)) in 6/8 clean reads), b3/b7 ~= min, b6 ~=
//     max; CAVEAT 2/8 reads (s27,s44) return an anomalous variant (b4=15) = a multiplex/poll
//     artifact, so the min/avg/max mapping is PLAUSIBLE not airtight.
//   - RESS 020C = FF-window LOW BYTE of 0209 word0 (PACK CURRENT), value-exact on aligned
//     samples (s27 ff1a, s44 ff b6 = 0209 0x05B6 discharge excursion, s48 ff2a) - CORRECTS the
//     low-hanging audit's "020C -> 0209 pack-V (mid byte)" fold-in (0209 is current, not V).
//   - VSC 0220 (refined 2026-07-28 over the full charge span): u16@4 = pack TERMINAL V, pinned
//     ~1 V/count across 361 V (s28 discharge sag) -> 402 V (full charge), matching broadcast
//     pack_v within +/-1-2 V - upgrades the prior single "~386 V" point. b0b1 (u16@0) is a
//     SEPARATE near-constant NOMINAL/rated ~392-396 V field (the "0x0189 setpoint" the doc had
//     dropped is real, just not the terminal node). b2=0x64=100, b7=0x32=50 stay static labels.
//   - RHCM 029A b2 = GENERAL BRAKE-APPLIED flag (0/1, front OR rear). *** DOWNGRADE 2026-07-29 r1
//     (adversarial QA): FRONT-SPECIFICITY REFUTED. *** b2 is a real, zero-anchored brake-applied
//     flag (r=0.99 s28 n=11 / 1.00 s44 n=8 vs broadcast front_brake_press; holds rest through
//     charge s48 = not a session artifact), but it is NOT front-specific. In s57 the lone b2=1
//     sample (t=57.4 s) coincides with a REAR-only brake: 0x133 D4=0x10 (rear pressed, within
//     0.41 s) while front pressure=0 (0x324 within 0.11 s) and the front lever=0 (0x15A D6=0). A
//     rear-only brake set b2 - so the earlier "RIGHT-hand module => right-hand front lever"
//     physical story does not hold; it flags EITHER brake. (Front-specificity DID survive for a
//     DIFFERENT signal - 0x128 D6 stays front-specific: 14 rear-only samples in s57 with D6 off.
//     Leave 0x128 D6 as-is.) [METHODOLOGY: before labeling a flag "front-X" require a matched
//     X-only counter-event (here a rear-only brake), not just an X-present correlation.] 029B
//     carries a small brake-linked sub-field (b2:b3 ~558-564, +/-6 ct) alongside its constant
//     ~1753/1754 reference-rail ADC = candidate. (The LEFT LHCM 029B/029C brake correlation is
//     a REJECTED collinear artifact - wrong hand.)
//   - VSC 0203 b2 = COARSE vehicle speed (~broadcast speed_raw / 10.1): r=1.000 vs broadcast
//     speed on s28 AND s44, 0 at standstill (parked + all charge sessions). Real but REDUNDANT
//     (a 4th speed copy after VSC 020C fine speed, EHCU 020F per-wheel, EHCU 0200 b0-1 head).
//   Full decoded catalogue: docs/livewire_s2_CAN_uds_data_map.md.
//
// ============================================================================
// STILL OPEN / TODO:
//  - (RESOLVED) 0x163 D2 is a 16-step BATTERY power bar, not continuous. The continuous
//    pack current + voltage ARE on secondary after all: 0x181 pack_current / pack_voltage
//    (see that frame) - so absolute battery watts = 0x181 V*I (verified vs the 0x186 Wh
//    meter to ~0.1 Wh over ride1). UDS RESS DID 0209 cross-checks the voltage.
//  - speed_ref2 (0x160 D3:D4): confirm = motor RPM, get scale.
//    (NOTE: front/rear brake are RESOLVED - front=0x15A, rear=0x133 D4. The old "0x136/
//    0x137 brake" guess is dead: 0x136 is a low-rate BCM status; 0x137 D1 is the startup
//    ignition/auth pulse (see the promoted 0x137 frame). Neither is a brake.)
//  - kickstand polarity (0x162 D6): which value = down.
//  - 0x134 D2/D3/D4 full mode+status enum across all modes (Rain/Eco low nibbles).
//  - (RESOLVED) battery % / SoC on secondary IS located: 0x185 D3:D4 upper 12 bits =
//    whole-percent SoC (see the 0x185 frame; UDS RESS DID 0213=88.3% cross-checks it).
// ============================================================================
